CM_ "IMPORT _hyundai_common.dbc";

BO_ 53 ACCELERATOR: 32 XXX
 SG_ CHECKSUM : 0|16@1+ (1,0) [0|65535] "" XXX
 SG_ COUNTER : 16|8@1+ (1,0) [0|255] "" XXX
 SG_ ACCELERATOR_PEDAL : 40|8@1+ (1,0) [0|255] "" XXX
 SG_ GEAR : 192|3@1+ (1,0) [0|7] "" XXX

BO_ 64 GEAR_ALT: 32 XXX
 SG_ CHECKSUM : 0|16@1+ (1,0) [0|65535] "" XXX
 SG_ COUNTER : 16|8@1+ (1,0) [0|255] "" XXX
 SG_ GEAR : 32|3@1+ (1,0) [0|7] "" XXX

BO_ 69 GEAR: 24 XXX
 SG_ CHECKSUM : 0|16@1+ (1,0) [0|65535] "" XXX
 SG_ COUNTER : 16|8@1+ (1,0) [0|255] "" XXX
 SG_ GEAR : 44|3@1+ (1,0) [0|7] "" XXX

BO_ 74 IMU_01_10ms: 32 CGW_CCU
 SG_ IMU_Crc1Val : 0|16@1+ (1,0) [0|0] "" ECS,ESC,FCU_C,GW_RGW,ICSC,MDPS,RCU,RWS,SFA,VPC_C
 SG_ IMU_AlvCnt1Val : 16|8@1+ (1,0) [0|0] "" ECS,ESC,FCU_C,GW_RGW,ICSC,MDPS,RCU,RWS,SFA,VPC_C
 SG_ IMU_YawSigSta : 24|4@1+ (1,0) [0|0] "" ESC,FCU_C,GW_RGW,MDPS,RCU,RWS,SFA,VPC_C
 SG_ IMU_LatAccelSigSta : 28|4@1+ (1,0) [0|0] "" ECS,ESC,FCU
 SG_ IMU_YawRtVal : 64|16@1+ (0.005,-163.84) [0|0] "º/s" ESC,FCU_C,GW_RGW,ICSC,MDPS,RCU,RWS,SFA,VPC_C
 SG_ IMU_LatAccelVal : 80|16@1+ (0.000127465,-4.17677312) [0|0] "g" ECS,ESC,FCU_C,GW_RGW,ICSC,MDPS,RCU,RWS,SFA,VPC_C

BO_ 96 ESP_STATUS: 32 XXX
 SG_ CHECKSUM : 0|16@1+ (1,0) [0|65535] "" XXX
 SG_ COUNTER : 16|8@1+ (1,0) [0|255] "" XXX
 SG_ TRACTION_AND_STABILITY_CONTROL : 42|3@1+ (1,0) [0|63] "" XXX
 SG_ BRAKE_PRESSURE : 128|10@1+ (1,0) [0|65535] "" XXX
 SG_ BRAKE_PRESSED : 148|1@1+ (1,0) [0|3] "" XXX

BO_ 101 BRAKE: 32 XXX
 SG_ CHECKSUM : 0|16@1+ (1,0) [0|65535] "" XXX
 SG_ COUNTER : 16|8@1+ (1,0) [0|255] "" XXX
 SG_ BRAKE_POSITION : 40|16@1- (1,0) [0|65535] "" XXX
 SG_ BRAKE_PRESSED : 57|1@1+ (1,0) [0|3] "" XXX

BO_ 112 GEAR_ALT_2: 32 XXX
 SG_ CHECKSUM : 0|16@1+ (1,0) [0|65535] "" XXX
 SG_ COUNTER : 16|8@1+ (1,0) [0|255] "" XXX
 SG_ GEAR : 60|3@1+ (1,0) [0|7] "" XXX

BO_ 160 WHL_01_10ms: 24 XXX
 SG_ WHL_Crc1Val : 0|16@1+ (1,0) [0|65535] "" XXX
 SG_ WHL_AlvCnt1Val : 16|8@1+ (1,0) [0|255] "" XXX
 SG_ WHL_PlsFLVal : 24|8@1+ (1,0) [0|255] "" XXX
 SG_ WHL_PlsFRVal : 32|8@1+ (1,0) [0|255] "" XXX
 SG_ WHL_PlsRLVal : 40|8@1+ (1,0) [0|255] "" XXX
 SG_ WHL_PlsRRVal : 48|8@1+ (1,0) [0|255] "" XXX
 SG_ WHL_DirFLVal : 56|2@1+ (1,0) [0|3] "" XXX
 SG_ WHL_DirFRVal : 58|2@1+ (1,0) [0|2] "" XXX
 SG_ WHL_DirRLVal : 60|2@1+ (1,0) [0|3] "" XXX
 SG_ WHL_DirRRVal : 62|2@1+ (1,0) [0|3] "" XXX
 SG_ WHL_SpdFLVal : 64|14@1+ (0.03125,0) [0|0] "km^h" XXX
 SG_ WHL_SpdFRVal : 80|14@1+ (0.03125,0) [0|0] "km^h" XXX
 SG_ WHL_SpdRLVal : 96|14@1+ (0.03125,0) [0|0] "km^h" XXX
 SG_ WHL_SpdRRVal : 112|14@1+ (0.03125,0) [0|0] "km^h" XXX
 SG_ WHL_SpdCalParmtr : 136|8@1+ (1,0) [0|255] "" XXX

BO_ 203 ADAS_CMD_35_10ms: 24 CGW_CCU
 SG_ ADAS_CMD_Crc35Val : 0|16@1+ (1,0) [0|0] "0" FCU_C,GW_RGW,MDPS,SFA
 SG_ ADAS_CMD_AlvCnt35Val : 16|8@1+ (1,0) [0|0] "0" FCU_C,GW_RGW,MDPS,SFA
 SG_ ADAS_ActvACISta : 24|4@1+ (1,0) [0|0] "" GW_RGW,MDPS,SFA
 SG_ ADAS_ActvACILvl2Sta : 28|4@1+ (1,0) [0|0] "" ESC,FCU_C,GW_RGW,MDPS,SFA,VPC_C
 SG_ ADAS_StrAnglReqVal : 32|14@1- (0.1,0) [0|0] "Deg" GW_RGW,MDPS,SFA
 SG_ ADAS_ACIAnglTqRedcGainVal : 48|8@1+ (0.004,0) [0|0] "" GW_RGW,MDPS,SFA
 SG_ FCA_ESA_ActvSta : 56|2@1+ (1,0) [0|0] "" GW_RGW,MDPS,SFA
 SG_ FCA_ESA_TqBstGainVal : 64|8@1+ (0.004,0) [0|0] "" GW_RGW,MDPS,SFA

BO_ 234 MDPS_01_10ms: 24 XXX
 SG_ MDPS_Crc1Val : 0|16@1+ (1,0) [0|0] "" XXX
 SG_ MDPS_AlvCnt1Val : 16|8@1+ (1,0) [0|0] "" XXX
 SG_ MDPS_WrngLmpSta : 24|3@1+ (1,0) [0|0] "" XXX
 SG_ MDPS_Typ : 27|3@1+ (1,0) [0|0] "" XXX
 SG_ MDPS_EngIdleRpmReq : 30|2@1+ (1,0) [0|0] "" XXX
 SG_ MDPS_VsmPlgInSta : 32|2@1+ (1,0) [0|0] "flag" XXX
 SG_ MDPS_VsmDfctvSta : 34|2@1+ (1,0) [0|0] "" XXX
 SG_ MDPS_VsmSigErrSta : 36|2@1+ (1,0) [0|0] "" XXX
 SG_ MDPS_PaPlugInSta : 38|2@1+ (1,0) [0|0] "" XXX
 SG_ MDPS_PaModeSta : 40|4@1+ (1,0) [0|0] "" XXX
 SG_ MDPS_PaCanfltSta : 44|2@1+ (1,0) [0|0] "" XXX
 SG_ MDPS_LkaPlgInSta : 46|2@1+ (1,0) [0|0] "" XXX
 SG_ MDPS_LkaToiActvSta : 48|2@1+ (1,0) [0|0] "" XXX
 SG_ MDPS_LkaToiUnblSta : 50|2@1+ (1,0) [0|0] "" XXX
 SG_ MDPS_LkaToiFltSta : 52|2@1+ (1,0) [0|0] "" XXX
 SG_ MDPS_LkaFailSta : 54|2@1+ (1,0) [0|0] "" XXX
 SG_ MDPS_ResetOpSta : 59|2@1+ (1,0) [0|0] "" XXX
 SG_ MDPS_CurrModVal : 61|3@1+ (1,0) [0|0] "" XXX
 SG_ MDPS_OutTqVal : 64|12@1+ (0.1,-204.8) [0|0] "Nm" XXX
 SG_ MDPS_VsmActResp : 76|2@1+ (1,0) [0|0] "" XXX
 SG_ Reprogram_State_MDPS : 78|2@1+ (1,0) [0|0] "" XXX
 SG_ MDPS_StrTqSnsrVal : 80|13@1+ (0.005,-20.48) [0|0] "Nm" XXX
 SG_ MDPS_PaStrAnglVal : 96|16@1- (0.1,0) [0|0] "Deg" XXX
 SG_ MDPS_LoamModSta : 112|2@1+ (1,0) [0|0] "" XXX
 SG_ MDPS_HDPSpprtSWVer : 114|5@1+ (1,0) [0|0] "" XXX
 SG_ MDPS_ADASAciActvSta : 120|4@1+ (1,0) [0|0] "" XXX
 SG_ MDPS_ADASAciPluginSta : 124|2@1+ (1,0) [0|0] "" XXX
 SG_ MDPS_ADAS_AciFltSig : 126|2@1+ (1,0) [0|0] "" XXX
 SG_ MDPS_EstStrAnglVal : 128|16@1- (0.1,0) [0|0] "Deg" XXX
 SG_ MDPS_ADASAciActvSta_Lv2 : 144|4@1+ (1,0) [0|0] "" XXX
 SG_ MDPS_ADAS_AciFltSig_Lv2 : 148|3@1+ (1,0) [0|0] "" XXX
 SG_ MDPS_TpaPlugInSta : 152|2@1+ (1,0) [0|0] "" XXX
 SG_ MDPS_TpaCanfltSta : 154|2@1+ (1,0) [0|0] "" XXX
 SG_ MDPS_TpaModeSta : 156|4@1+ (1,0) [0|0] "" XXX
 SG_ MDPS_TpaStrAnglVal : 160|16@1- (0.1,0) [0|0] "Deg" XXX

BO_ 256 ACCELERATOR_BRAKE_ALT: 32 XXX
 SG_ CHECKSUM : 0|16@1+ (1,0) [0|65535] "" XXX
 SG_ COUNTER : 16|8@1+ (1,0) [0|255] "" XXX
 SG_ BRAKE_PRESSED : 32|1@1+ (1,0) [0|1] "" XXX
 SG_ ACCELERATOR_PEDAL_PRESSED : 176|1@1+ (1,0) [0|1] "" XXX

BO_ 261 ACCELERATOR_ALT: 32 XXX
 SG_ CHECKSUM : 0|16@1+ (1,0) [0|65535] "" XXX
 SG_ COUNTER : 16|8@1+ (1,0) [0|255] "" XXX
 SG_ ACCELERATOR_PEDAL : 103|10@1+ (0.25,0) [0|1022] "" XXX

BO_ 272 LKAS_ALT: 32 XXX
 SG_ CHECKSUM : 0|16@1+ (1,0) [0|65535] "" XXX
 SG_ COUNTER : 16|8@1+ (1,0) [0|255] "" XXX
 SG_ LKA_MODE : 24|3@1+ (1,0) [0|7] "" XXX
 SG_ LKA_AVAILABLE : 27|2@1+ (1,0) [0|255] "" XXX
 SG_ LKA_WARNING : 32|1@1+ (1,0) [0|1] "" XXX
 SG_ LKA_ICON : 38|2@1+ (1,0) [0|255] "" XXX
 SG_ FCA_SYSWARN : 40|1@0+ (1,0) [0|1] "" XXX
 SG_ TORQUE_REQUEST : 41|11@1+ (1,-1024) [0|4095] "" XXX
 SG_ STEER_REQ : 52|1@1+ (1,0) [0|1] "" XXX
 SG_ LFA_BUTTON : 56|1@1+ (1,0) [0|255] "" XXX
 SG_ LKA_ASSIST : 62|1@1+ (1,0) [0|1] "" XXX
 SG_ STEER_MODE : 65|3@1+ (1,0) [0|1] "" XXX
 SG_ NEW_SIGNAL_2 : 70|2@0+ (1,0) [0|3] "" XXX
 SG_ LKAS_ANGLE_ACTIVE : 77|2@0+ (1,0) [0|3] "" XXX
 SG_ HAS_LANE_SAFETY : 80|1@0+ (1,0) [0|1] "" XXX
 SG_ LKAS_ANGLE_CMD : 82|14@1- (0.1,0) [0|511] "" XXX
 SG_ LKAS_ANGLE_MAX_TORQUE : 96|8@1+ (1,0) [0|255] "" XXX
 SG_ NEW_SIGNAL_3 : 111|8@0+ (1,0) [0|255] "" XXX

BO_ 293 SAS_01_10ms: 16 XXX
 SG_ SAS_Crc1Val : 0|16@1+ (1,0) [0|0] "" XXX
 SG_ SAS_AlvCnt1Val : 16|8@1+ (1,0) [0|0] "" XXX
 SG_ SAS_AnglVal : 24|16@1- (0.1,0) [0|0] "Deg" XXX
 SG_ SAS_SpdVal : 40|8@1+ (4,0) [0|0] "Deg/s" XXX
 SG_ SAS_IntSta : 48|8@1+ (1,0) [0|0] "" XXX

BO_ 298 ADAS_CMD_30_10ms: 16 ADRV
 SG_ ADAS_CMD_Crc30Val : 0|16@1+ (1,0) [0|65535] "" ADRV
 SG_ ADAS_CMD_AlvCnt30Val : 16|8@1+ (1,0) [0|255] "" ADRV
 SG_ LKA_OptUsmSta : 24|3@1+ (1,0) [0|7] "" ADRV
 SG_ LKA_RcgSta : 27|2@1+ (1,0) [0|255] "" ADRV
 SG_ LKA_LHLnWrnSta : 30|2@1+ (1,0) [0|3] "" ADRV
 SG_ LKA_RHLnWrnSta : 32|1@1+ (1,0) [0|1] "" ADRV
 SG_ LKA_HndsoffSnd : 34|4@1+ (1,0) [0|15] "" ADRV
 SG_ LKA_SysIndReq : 38|2@1+ (1,0) [0|255] "" ADRV
 SG_ ADAS_StrTqReqVal : 41|11@1+ (1,-1024) [0|4095] "" ADRV
 SG_ ADAS_ActToiSta : 52|1@1+ (1,0) [0|1] "" ADRV
 SG_ ADAS_ToiFltSta : 54|2@1+ (1,0) [0|3] "" ADRV
 SG_ LFA_BUTTON : 56|1@1+ (1,0) [0|255] "" ADRV
 SG_ LKA_SysWrn : 60|2@1+ (1,0) [0|3] "" ADRV
 SG_ LKA_ASSIST : 62|1@1+ (1,0) [0|1] "" ADRV
 SG_ FCA_LO_WrnSta : 64|1@1+ (1,0) [0|1] "" ADRV
 SG_ STEER_MODE : 65|3@1+ (1,0) [0|1] "" ADRV
 SG_ FCA_LS_WrnSta : 68|2@1+ (1,0) [0|3] "" ADRV
 SG_ NEW_SIGNAL_2 : 70|2@0+ (1,0) [0|3] "" ADRV
 SG_ SCC_TakeoverReq_CLU_AMP_PE_02_Warn_Sound : 72|8@1+ (1,0) [0|255] "" ADRV
 SG_ LKA_UsmMod : 80|1@0+ (1,0) [0|1] "" ADRV
 SG_ ELK_SysFlrSta : 85|5@1+ (1,0) [0|31] "" ADRV
 SG_ ELK_SymbDisp : 90|3@1+ (1,0) [0|7] "" ADRV
 SG_ FCA_ESA_WrnSta : 93|8@1+ (1,0) [0|255] "" ADRV
 SG_ FCA_ESA_CtrlSta : 101|3@1+ (1,0) [0|7] "" ADRV
 SG_ ADAS_Damping_Gain : 104|7@1+ (1,0) [0|127] "" ADRV
 SG_ NEW_SIGNAL_3 : 111|8@0+ (1,0) [0|255] "" ADRV

BO_ 304 GEAR_SHIFTER: 16 XXX
 SG_ CHECKSUM : 0|16@1+ (1,0) [0|65535] "" XXX
 SG_ COUNTER : 16|8@1+ (1,0) [0|255] "" XXX
 SG_ PARK_BUTTON : 32|2@1+ (1,0) [0|3] "" XXX
 SG_ KNOB_POSITION : 40|3@1+ (1,0) [0|3] "" XXX
 SG_ GEAR : 64|3@1+ (1,0) [0|7] "" XXX

BO_ 352 ADRV_0x160: 16 ADRV
 SG_ CHECKSUM : 0|16@1+ (1,0) [0|65535] "" XXX
 SG_ COUNTER : 16|8@1+ (1,0) [0|255] "" XXX
 SG_ AEB_SETTING : 24|2@1+ (1,0) [0|255] "" XXX
 SG_ SET_ME_2 : 56|8@1+ (1,0) [0|1] "" XXX
 SG_ SET_ME_FF : 64|8@1+ (1,0) [0|255] "" XXX
 SG_ SET_ME_FC : 72|8@1+ (1,0) [0|255] "" XXX
 SG_ SET_ME_9 : 80|8@1+ (1,0) [0|255] "" XXX

BO_ 353 CCNC_0x161: 32 CCNC
 SG_ CHECKSUM : 0|16@1+ (1,0) [0|65535] "" XXX
 SG_ COUNTER : 16|8@1+ (1,0) [0|255] "" XXX
 SG_ FCA_ICON : 24|3@1+ (1,0) [0|7] "" XXX
 SG_ FCA_ALT_ICON : 27|3@1+ (1,0) [0|7] "" XXX
 SG_ LKA_ICON : 30|3@1+ (1,0) [0|3] "" XXX
 SG_ HBA_ICON : 33|3@1+ (1,0) [0|7] "" XXX
 SG_ ZEROS_1 : 36|4@1+ (1,0) [0|15] "" XXX
 SG_ ZEROS_2 : 40|2@1+ (1,0) [0|3] "" XXX
 SG_ FCA_IMAGE : 42|3@1+ (1,0) [0|7] "" XXX
 SG_ ZEROS_3 : 45|3@1+ (1,0) [0|7] "" XXX
 SG_ ZEROS_4 : 48|3@1+ (1,0) [0|7] "" XXX
 SG_ BCA_LEFT : 51|3@1+ (1,0) [0|7] "" XXX
 SG_ BCA_RIGHT : 54|3@1+ (1,0) [0|7] "" XXX
 SG_ LCA_LEFT_ARROW : 57|3@1+ (1,0) [0|7] "" XXX
 SG_ LCA_RIGHT_ARROW : 60|3@1+ (1,0) [0|7] "" XXX
 SG_ ZEROS_5 : 63|1@0+ (1,0) [0|1] "" XXX
 SG_ CENTERLINE : 64|2@1+ (1,0) [0|3] "" XXX
 SG_ TARGET : 66|3@1+ (1,0) [0|7] "" XXX
 SG_ TARGET_DISTANCE : 69|11@1+ (0.1,0) [0|204.7] "m" XXX
 SG_ LANELINE_LEFT : 80|4@1+ (1,0) [0|15] "" XXX
 SG_ LANELINE_LEFT_POSITION : 84|6@1+ (1,0) [0|15] "" XXX
 SG_ LANELINE_RIGHT : 90|4@1+ (1,0) [0|15] "" XXX
 SG_ LANELINE_RIGHT_POSITION : 94|6@1+ (1,0) [0|3] "" XXX
 SG_ LANELINE_CURVATURE : 100|5@1- (1,15) [0|31] "" XXX
 SG_ LANE_HIGHLIGHT : 105|4@1+ (1,0) [0|15] "" XXX
 SG_ LANE_HIGHLIGHT_DISTANCE : 109|11@1+ (0.1,0) [0|204.7] "m" XXX
 SG_ LANE_LEFT : 120|3@1+ (1,0) [0|7] "" XXX
 SG_ LANE_RIGHT : 123|3@1+ (1,0) [0|7] "" XXX
 SG_ LANE_ZOOM : 126|2@1+ (1,0) [0|3] "" XXX
 SG_ ALERTS_1 : 128|6@1+ (1,0) [0|63] "" XXX
 SG_ ALERTS_2 : 134|5@1+ (1,0) [0|3] "" XXX
 SG_ ALERTS_3 : 139|5@1+ (1,0) [0|15] "" XXX
 SG_ ALERTS_4 : 144|8@1+ (1,0) [0|511] "" XXX
 SG_ ALERTS_5 : 152|5@1+ (1,0) [0|7] "" XXX
 SG_ MUTE : 157|3@1+ (1,0) [0|7] "" XXX
 SG_ SOUNDS_1 : 160|4@1+ (1,0) [0|3] "" XXX
 SG_ SOUNDS_2 : 164|4@1+ (1,0) [0|3] "" XXX
 SG_ SOUNDS_3 : 168|4@1+ (1,0) [0|15] "" XXX
 SG_ SOUNDS_4 : 172|3@1+ (1,0) [0|7] "" XXX
 SG_ ZEROS_6 : 175|1@0+ (1,0) [0|1] "" XXX
 SG_ ZEROS_7 : 176|5@1+ (1,0) [0|31] "" XXX
 SG_ SETSPEED_HUD : 181|3@1+ (1,0) [0|3] "" XXX
 SG_ DISTANCE_LEAD : 184|5@1+ (1,0) [0|31] "" XXX
 SG_ DISTANCE_CAR : 189|3@1+ (1,0) [0|7] "" XXX
 SG_ DISTANCE_SPACING : 192|4@1+ (1,0) [0|15] "" XXX
 SG_ DISTANCE : 196|4@1+ (1,0) [0|7] "" XXX
 SG_ SETSPEED_SPEED : 200|8@1+ (1,0) [0|255] "" XXX
 SG_ SETSPEED : 208|4@1+ (1,0) [0|3] "" XXX
 SG_ HDA_ICON : 212|4@1+ (1,0) [0|3] "" XXX
 SG_ SLA_ICON : 216|4@1+ (1,0) [0|15] "" XXX
 SG_ NAV_ICON : 220|4@1+ (1,0) [0|3] "" XXX
 SG_ LFA_ICON : 224|4@1+ (1,0) [0|3] "" XXX
 SG_ LCA_LEFT_ICON : 228|4@1+ (1,0) [0|15] "" XXX
 SG_ LCA_RIGHT_ICON : 232|4@1+ (1,0) [0|15] "" XXX
 SG_ BACKGROUND : 236|4@1+ (1,0) [0|15] "" XXX
 SG_ DAW_ICON : 240|3@1+ (1,0) [0|7] "" XXX
 SG_ CAR_CIRCLE : 243|3@1+ (1,0) [0|7] "" XXX
 SG_ ZEROS_8 : 246|2@1+ (1,0) [0|3] "" XXX
 SG_ ZEROS_9 : 248|8@1+ (1,0) [0|255] "" XXX

BO_ 354 CCNC_0x162: 32 CCNC
 SG_ CHECKSUM : 0|16@1+ (1,0) [0|65535] "" XXX
 SG_ COUNTER : 16|8@1+ (1,0) [0|255] "" XXX
 SG_ COUNTRY : 24|4@1+ (1,0) [0|7] "" XXX
 SG_ SPEEDLIMIT_FLASH : 28|4@1+ (1,0) [0|15] "" XXX
 SG_ SPEEDLIMIT : 32|8@1+ (1,0) [0|255] "" XXX
 SG_ SIGNS : 40|8@1+ (1,0) [0|15] "" XXX
 SG_ SPEEDLIMIT_WEATHER : 48|4@1+ (1,0) [0|15] "" XXX
 SG_ VIBRATE : 52|3@1+ (1,0) [0|7] "" XXX
 SG_ ZEROS_1 : 55|1@0+ (1,0) [0|1] "" XXX
 SG_ ZEROS_2 : 56|8@1+ (1,0) [0|255] "" XXX
 SG_ LEAD : 64|5@1+ (1,0) [0|31] "" XXX
 SG_ LEAD_DISTANCE : 69|11@1+ (0.1,0) [0|204.7] "m" XXX
 SG_ LEAD_LATERAL : 80|7@1+ (0.1,0) [0|127] "m" XXX
 SG_ ZEROS_3 : 87|1@0+ (1,0) [0|1] "" XXX
 SG_ LEAD_ALT : 88|5@1+ (1,0) [0|31] "" XXX
 SG_ LEAD_ALT_DISTANCE : 93|11@1+ (0.1,0) [0|204.7] "m" XXX
 SG_ LEAD_ALT_LATERAL : 104|7@1+ (0.1,0) [0|127] "m" XXX
 SG_ ZEROS_4 : 111|1@0+ (1,0) [0|1] "" XXX
 SG_ LEAD_LEFT : 112|5@1+ (1,0) [0|31] "" XXX
 SG_ LEAD_LEFT_DISTANCE : 117|11@1+ (0.1,0) [0|204.7] "m" XXX
 SG_ LEAD_LEFT_LATERAL : 128|7@1+ (0.1,0) [0|127] "m" XXX
 SG_ ZEROS_5 : 135|1@0+ (1,0) [0|1] "" XXX
 SG_ LEAD_RIGHT : 136|5@1+ (1,0) [0|31] "" XXX
 SG_ LEAD_RIGHT_DISTANCE : 141|11@1+ (0.1,0) [0|204.7] "m" XXX
 SG_ LEAD_RIGHT_LATERAL : 152|7@1+ (0.1,0) [0|127] "m" XXX
 SG_ ZEROS_6 : 159|1@0+ (1,0) [0|1] "" XXX
 SG_ ZEROS_7 : 162|3@0+ (1,0) [0|7] "" XXX
 SG_ LEAD_LEFT_REAR_STATUS : 167|5@0+ (1,0) [0|31] "" XXX
 SG_ LEAD_LEFT_REAR_DISTANCE : 175|8@0+ (0.1,0) [0|255] "m" XXX
 SG_ LEAD_LEFT_REAR_LATERAL : 182|7@0+ (0.1,0) [0|127] "m" XXX
 SG_ ZEROS_8 : 183|1@0+ (1,0) [0|1] "" XXX
 SG_ ZEROS_9 : 191|8@0+ (1,0) [0|255] "" XXX
 SG_ LEAD_RIGHT_REAR_STATUS : 196|5@0+ (1,0) [0|31] "" XXX
 SG_ LEAD_RIGHT_REAR_DISTANCE : 197|8@1+ (0.1,0) [0|255] "m" XXX
 SG_ LEAD_RIGHT_REAR_LATERAL : 205|7@1+ (0.1,0) [0|127] "m" XXX
 SG_ ZEROS_10 : 212|1@0+ (1,0) [0|1] "" XXX
 SG_ FAULT_FSS : 213|3@1+ (1,0) [0|7] "" XXX
 SG_ FAULT_FCA : 216|3@1+ (1,0) [0|7] "" XXX
 SG_ FAULT_LSS : 219|3@1+ (1,0) [0|7] "" XXX
 SG_ FAULT_SLA : 222|3@1+ (1,0) [0|7] "" XXX
 SG_ FAULT_DAW : 225|3@1+ (1,0) [0|7] "" XXX
 SG_ FAULT_HBA : 228|3@1+ (1,0) [0|7] "" XXX
 SG_ FAULT_SCC : 231|3@1+ (1,0) [0|7] "" XXX
 SG_ FAULT_LFA : 234|3@1+ (1,0) [0|7] "" XXX
 SG_ FAULT_HDA : 237|3@1+ (1,0) [0|7] "" XXX
 SG_ FAULT_LCA : 240|3@1+ (1,0) [0|7] "" XXX
 SG_ FAULT_HDP : 243|3@1+ (1,0) [0|7] "" XXX
 SG_ FAULT_DAS : 246|3@1+ (1,0) [0|7] "" XXX
 SG_ FAULT_ESS : 249|3@1+ (1,0) [0|7] "" XXX
 SG_ ZEROS_11 : 252|4@1+ (1,0) [0|15] "" XXX

BO_ 357 SPAS1: 24 APRK
 SG_ CHECKSUM : 0|16@1+ (1,0) [0|65535] "" XXX
 SG_ COUNTER : 16|8@1+ (1,0) [0|0] "" XXX
 SG_ NEW_SIGNAL_2 : 90|3@1+ (1,0) [0|0] "" XXX
 SG_ NEW_SIGNAL_1 : 96|16@1- (0.1,0) [0|0] "" XXX

BO_ 362 SPAS2: 32 APRK
 SG_ CHECKSUM : 0|16@1+ (1,0) [0|65535] "" XXX
 SG_ COUNTER : 16|8@1+ (1,0) [0|0] "" XXX
 SG_ BLINKER_CONTROL : 133|3@1+ (1,0) [0|0] "" XXX

BO_ 373 TCS: 24 XXX
 SG_ CHECKSUM : 0|16@1+ (1,0) [0|65535] "" XXX
 SG_ COUNTER : 16|8@1+ (1,0) [0|255] "" XXX
 SG_ NEW_SIGNAL_4 : 24|7@1+ (1,0) [0|127] "" XXX
 SG_ aBasis : 32|11@1+ (0.01,-10.23) [0|7] "m/s^2" XXX
 SG_ ACCEL_REF_ACC : 48|11@1- (1,0) [0|1023] "" XXX
 SG_ EQUIP_MAYBE : 64|1@0+ (1,0) [0|1] "" XXX
 SG_ ACCEnable : 67|2@0+ (1,0) [0|3] "" XXX
 SG_ ACC_REQ : 68|1@0+ (1,0) [0|1] "" XXX
 SG_ NEW_SIGNAL_5 : 72|1@0+ (1,0) [0|1] "" XXX
 SG_ NEW_SIGNAL_2 : 74|1@0+ (1,0) [0|1] "" XXX
 SG_ NEW_SIGNAL_3 : 76|1@0+ (1,0) [0|1] "" XXX
 SG_ NEW_SIGNAL_1 : 80|1@0+ (1,0) [0|1] "" XXX
 SG_ DriverBraking : 81|1@0+ (1,0) [0|1] "" XXX
 SG_ DriverBrakingLowSens : 84|1@1+ (1,0) [0|1] "" XXX
 SG_ AEB_EQUIP_MAYBE : 96|1@0+ (1,0) [0|1] "" XXX
 SG_ NEW_SIGNAL_6 : 128|4@1+ (1,0) [0|15] "" XXX
 SG_ NEW_SIGNAL_7 : 135|2@0+ (1,0) [0|3] "" XXX
 SG_ PROBABLY_EQUIP : 136|2@1+ (1,0) [0|3] "" XXX

BO_ 384 L_FR_CMR_Obj_01_30ms: 32 FR_CMR
 SG_ FR_CMR_Obj_Crc01Val : 0|16@1+ (1,0) [0|65535] "" ADAS_DRV
 SG_ FR_CMR_Obj_AlvCnt01Val : 16|8@1+ (1,0) [0|255] "" ADAS_DRV
 SG_ FR_CMR_Obj_QualLvl01Sta : 24|7@1+ (1,0) [0|100] "%" ADAS_DRV
 SG_ FR_CMR_Obj_AlvAge01Val : 32|8@1+ (1,0) [0|255] "" ADAS_DRV
 SG_ FR_CMR_Obj_MvngFlag01Sta : 40|4@1+ (1,0) [0|9] "" ADAS_DRV
 SG_ FR_CMR_Obj_Id01Val : 44|7@1+ (1,0) [0|127] "" ADAS_DRV
 SG_ FR_CMR_Obj_Wth01Val : 52|7@1+ (0.05,0) [0|6.35] "m" ADAS_DRV
 SG_ FR_CMR_Obj_Clfct01Sta : 60|3@1+ (1,0) [0|6] "" ADAS_DRV
 SG_ FR_CMR_Obj_RelPosX01Val : 64|13@1+ (0.05,0) [0|350] "m" ADAS_DRV
 SG_ FR_CMR_Obj_RelPosY01Val : 78|12@1+ (0.05,-102.4) [-102.4|102.35] "m" ADAS_DRV
 SG_ FR_CMR_Obj_RelVelX01Val : 91|12@1+ (0.05,-100) [-100|100] "m/s" ADAS_DRV
 SG_ FR_CMR_Obj_RelVelY01Val : 104|10@1+ (0.05,-25) [-25|25] "m/s" ADAS_DRV
 SG_ FR_CMR_Obj_RelAccelX01Val : 115|9@1- (0.05,0) [-12.8|12.75] "m/s^2" ADAS_DRV
 SG_ FR_CMR_Obj_QualLvl02Sta : 152|7@1+ (1,0) [0|100] "%" ADAS_DRV
 SG_ FR_CMR_Obj_AlvAge02Val : 160|8@1+ (1,0) [0|255] "" ADAS_DRV
 SG_ FR_CMR_Obj_MvngFlag02Sta : 168|4@1+ (1,0) [0|9] "" ADAS_DRV
 SG_ FR_CMR_Obj_Id02Val : 172|7@1+ (1,0) [0|127] "" ADAS_DRV
 SG_ FR_CMR_Obj_Wth02Val : 180|7@1+ (0.05,0) [0|6.35] "m" ADAS_DRV
 SG_ FR_CMR_Obj_Clfct02Sta : 188|3@1+ (1,0) [0|6] "" ADAS_DRV
 SG_ FR_CMR_Obj_RelPosX02Val : 192|13@1+ (0.05,0) [0|350] "m" ADAS_DRV
 SG_ FR_CMR_Obj_RelPosY02Val : 206|12@1+ (0.05,-102.4) [-102.4|102.35] "m" ADAS_DRV
 SG_ FR_CMR_Obj_RelVelX02Val : 219|12@1+ (0.05,-100) [-100|100] "m/s" ADAS_DRV
 SG_ FR_CMR_Obj_RelVelY02Val : 232|10@1+ (0.05,-25) [-25|25] "m/s" ADAS_DRV
 SG_ FR_CMR_Obj_RelAccelX02Val : 243|9@1- (0.05,0) [-12.8|12.75] "m/s^2" ADAS_DRV

BO_ 385 L_FR_CMR_Obj_02_30ms: 32 FR_CMR
 SG_ FR_CMR_Obj_Crc02Val : 0|16@1+ (1,0) [0|65535] "" ADAS_DRV
 SG_ FR_CMR_Obj_AlvCnt02Val : 16|8@1+ (1,0) [0|255] "" ADAS_DRV
 SG_ FR_CMR_Obj_QualLvl03Sta : 24|7@1+ (1,0) [0|100] "%" ADAS_DRV
 SG_ FR_CMR_Obj_AlvAge03Val : 32|8@1+ (1,0) [0|255] "" ADAS_DRV
 SG_ FR_CMR_Obj_MvngFlag03Sta : 40|4@1+ (1,0) [0|9] "" ADAS_DRV
 SG_ FR_CMR_Obj_Id03Val : 44|7@1+ (1,0) [0|127] "" ADAS_DRV
 SG_ FR_CMR_Obj_Wth03Val : 52|7@1+ (0.05,0) [0|6.35] "m" ADAS_DRV
 SG_ FR_CMR_Obj_Clfct03Sta : 60|3@1+ (1,0) [0|6] "" ADAS_DRV
 SG_ FR_CMR_Obj_RelPosX03Val : 64|13@1+ (0.05,0) [0|350] "m" ADAS_DRV
 SG_ FR_CMR_Obj_RelPosY03Val : 78|12@1+ (0.05,-102.4) [-102.4|102.35] "m" ADAS_DRV
 SG_ FR_CMR_Obj_RelVelX03Val : 91|12@1+ (0.05,-100) [-100|100] "m/s" ADAS_DRV
 SG_ FR_CMR_Obj_RelVelY03Val : 104|10@1+ (0.05,-25) [-25|25] "m/s" ADAS_DRV
 SG_ FR_CMR_Obj_RelAccelX03Val : 115|9@1- (0.05,0) [-12.8|12.75] "m/s^2" ADAS_DRV
 SG_ FR_CMR_Obj_QualLvl04Sta : 152|7@1+ (1,0) [0|100] "%" ADAS_DRV
 SG_ FR_CMR_Obj_AlvAge04Val : 160|8@1+ (1,0) [0|255] "" ADAS_DRV
 SG_ FR_CMR_Obj_MvngFlag04Sta : 168|4@1+ (1,0) [0|9] "" ADAS_DRV
 SG_ FR_CMR_Obj_Id04Val : 172|7@1+ (1,0) [0|127] "" ADAS_DRV
 SG_ FR_CMR_Obj_Wth04Val : 180|7@1+ (0.05,0) [0|6.35] "m" ADAS_DRV
 SG_ FR_CMR_Obj_Clfct04Sta : 188|3@1+ (1,0) [0|6] "" ADAS_DRV
 SG_ FR_CMR_Obj_RelPosX04Val : 192|13@1+ (0.05,0) [0|350] "m" ADAS_DRV
 SG_ FR_CMR_Obj_RelPosY04Val : 206|12@1+ (0.05,-102.4) [-102.4|102.35] "m" ADAS_DRV
 SG_ FR_CMR_Obj_RelVelX04Val : 219|12@1+ (0.05,-100) [-100|100] "m/s" ADAS_DRV
 SG_ FR_CMR_Obj_RelVelY04Val : 232|10@1+ (0.05,-25) [-25|25] "m/s" ADAS_DRV
 SG_ FR_CMR_Obj_RelAccelX04Val : 243|9@1- (0.05,0) [-12.8|12.75] "m/s^2" ADAS_DRV

BO_ 386 L_FR_CMR_Obj_03_30ms: 32 FR_CMR
 SG_ FR_CMR_Obj_Crc03Val : 0|16@1+ (1,0) [0|65535] "" ADAS_DRV
 SG_ FR_CMR_Obj_AlvCnt03Val : 16|8@1+ (1,0) [0|255] "" ADAS_DRV
 SG_ FR_CMR_Obj_QualLvl05Sta : 24|7@1+ (1,0) [0|100] "%" ADAS_DRV
 SG_ FR_CMR_Obj_AlvAge05Val : 32|8@1+ (1,0) [0|255] "" ADAS_DRV
 SG_ FR_CMR_Obj_MvngFlag05Sta : 40|4@1+ (1,0) [0|9] "" ADAS_DRV
 SG_ FR_CMR_Obj_Id05Val : 44|7@1+ (1,0) [0|127] "" ADAS_DRV
 SG_ FR_CMR_Obj_Wth05Val : 52|7@1+ (0.05,0) [0|6.35] "m" ADAS_DRV
 SG_ FR_CMR_Obj_Clfct05Sta : 60|3@1+ (1,0) [0|6] "" ADAS_DRV
 SG_ FR_CMR_Obj_RelPosX05Val : 64|13@1+ (0.05,0) [0|350] "m" ADAS_DRV
 SG_ FR_CMR_Obj_RelPosY05Val : 78|12@1+ (0.05,-102.4) [-102.4|102.35] "m" ADAS_DRV
 SG_ FR_CMR_Obj_RelVelX05Val : 91|12@1+ (0.05,-100) [-100|100] "m/s" ADAS_DRV
 SG_ FR_CMR_Obj_RelVelY05Val : 104|10@1+ (0.05,-25) [-25|25] "m/s" ADAS_DRV
 SG_ FR_CMR_Obj_RelAccelX05Val : 115|9@1- (0.05,0) [-12.8|12.75] "m/s^2" ADAS_DRV
 SG_ FR_CMR_Obj_QualLvl06Sta : 152|7@1+ (1,0) [0|100] "%" ADAS_DRV
 SG_ FR_CMR_Obj_AlvAge06Val : 160|8@1+ (1,0) [0|255] "" ADAS_DRV
 SG_ FR_CMR_Obj_MvngFlag06Sta : 168|4@1+ (1,0) [0|9] "" ADAS_DRV
 SG_ FR_CMR_Obj_Id06Val : 172|7@1+ (1,0) [0|127] "" ADAS_DRV
 SG_ FR_CMR_Obj_Wth06Val : 180|7@1+ (0.05,0) [0|6.35] "m" ADAS_DRV
 SG_ FR_CMR_Obj_Clfct06Sta : 188|3@1+ (1,0) [0|6] "" ADAS_DRV
 SG_ FR_CMR_Obj_RelPosX06Val : 192|13@1+ (0.05,0) [0|350] "m" ADAS_DRV
 SG_ FR_CMR_Obj_RelPosY06Val : 206|12@1+ (0.05,-102.4) [-102.4|102.35] "m" ADAS_DRV
 SG_ FR_CMR_Obj_RelVelX06Val : 219|12@1+ (0.05,-100) [-100|100] "m/s" ADAS_DRV
 SG_ FR_CMR_Obj_RelVelY06Val : 232|10@1+ (0.05,-25) [-25|25] "m/s" ADAS_DRV
 SG_ FR_CMR_Obj_RelAccelX06Val : 243|9@1- (0.05,0) [-12.8|12.75] "m/s^2" ADAS_DRV

BO_ 387 L_FR_CMR_Obj_04_30ms: 32 FR_CMR
 SG_ FR_CMR_Obj_Crc04Val : 0|16@1+ (1,0) [0|65535] "" ADAS_DRV
 SG_ FR_CMR_Obj_AlvCnt04Val : 16|8@1+ (1,0) [0|255] "" ADAS_DRV
 SG_ FR_CMR_Obj_QualLvl07Sta : 24|7@1+ (1,0) [0|100] "%" ADAS_DRV
 SG_ FR_CMR_Obj_AlvAge07Val : 32|8@1+ (1,0) [0|255] "" ADAS_DRV
 SG_ FR_CMR_Obj_MvngFlag07Sta : 40|4@1+ (1,0) [0|9] "" ADAS_DRV
 SG_ FR_CMR_Obj_Id07Val : 44|7@1+ (1,0) [0|127] "" ADAS_DRV
 SG_ FR_CMR_Obj_Wth07Val : 52|7@1+ (0.05,0) [0|6.35] "m" ADAS_DRV
 SG_ FR_CMR_Obj_Clfct07Sta : 60|3@1+ (1,0) [0|6] "" ADAS_DRV
 SG_ FR_CMR_Obj_RelPosX07Val : 64|13@1+ (0.05,0) [0|350] "m" ADAS_DRV
 SG_ FR_CMR_Obj_RelPosY07Val : 78|12@1+ (0.05,-102.4) [-102.4|102.35] "m" ADAS_DRV
 SG_ FR_CMR_Obj_RelVelX07Val : 91|12@1+ (0.05,-100) [-100|100] "m/s" ADAS_DRV
 SG_ FR_CMR_Obj_RelVelY07Val : 104|10@1+ (0.05,-25) [-25|25] "m/s" ADAS_DRV
 SG_ FR_CMR_Obj_RelAccelX07Val : 115|9@1- (0.05,0) [-12.8|12.75] "m/s^2" ADAS_DRV
 SG_ FR_CMR_Obj_QualLvl08Sta : 152|7@1+ (1,0) [0|100] "%" ADAS_DRV
 SG_ FR_CMR_Obj_AlvAge08Val : 160|8@1+ (1,0) [0|255] "" ADAS_DRV
 SG_ FR_CMR_Obj_MvngFlag08Sta : 168|4@1+ (1,0) [0|9] "" ADAS_DRV
 SG_ FR_CMR_Obj_Id08Val : 172|7@1+ (1,0) [0|127] "" ADAS_DRV
 SG_ FR_CMR_Obj_Wth08Val : 180|7@1+ (0.05,0) [0|6.35] "m" ADAS_DRV
 SG_ FR_CMR_Obj_Clfct08Sta : 188|3@1+ (1,0) [0|6] "" ADAS_DRV
 SG_ FR_CMR_Obj_RelPosX08Val : 192|13@1+ (0.05,0) [0|350] "m" ADAS_DRV
 SG_ FR_CMR_Obj_RelPosY08Val : 206|12@1+ (0.05,-102.4) [-102.4|102.35] "m" ADAS_DRV
 SG_ FR_CMR_Obj_RelVelX08Val : 219|12@1+ (0.05,-100) [-100|100] "m/s" ADAS_DRV
 SG_ FR_CMR_Obj_RelVelY08Val : 232|10@1+ (0.05,-25) [-25|25] "m/s" ADAS_DRV
 SG_ FR_CMR_Obj_RelAccelX08Val : 243|9@1- (0.05,0) [-12.8|12.75] "m/s^2" ADAS_DRV

BO_ 388 L_FR_CMR_Obj_05_30ms: 32 FR_CMR
 SG_ FR_CMR_Obj_Crc05Val : 0|16@1+ (1,0) [0|65535] "" ADAS_DRV
 SG_ FR_CMR_Obj_AlvCnt05Val : 16|8@1+ (1,0) [0|255] "" ADAS_DRV
 SG_ FR_CMR_Obj_QualLvl09Sta : 24|7@1+ (1,0) [0|100] "%" ADAS_DRV
 SG_ FR_CMR_Obj_AlvAge09Val : 32|8@1+ (1,0) [0|255] "" ADAS_DRV
 SG_ FR_CMR_Obj_MvngFlag09Sta : 40|4@1+ (1,0) [0|9] "" ADAS_DRV
 SG_ FR_CMR_Obj_Id09Val : 44|7@1+ (1,0) [0|127] "" ADAS_DRV
 SG_ FR_CMR_Obj_Wth09Val : 52|7@1+ (0.05,0) [0|6.35] "m" ADAS_DRV
 SG_ FR_CMR_Obj_Clfct09Sta : 60|3@1+ (1,0) [0|6] "" ADAS_DRV
 SG_ FR_CMR_Obj_RelPosX09Val : 64|13@1+ (0.05,0) [0|350] "m" ADAS_DRV
 SG_ FR_CMR_Obj_RelPosY09Val : 78|12@1+ (0.05,-102.4) [-102.4|102.35] "m" ADAS_DRV
 SG_ FR_CMR_Obj_RelVelX09Val : 91|12@1+ (0.05,-100) [-100|100] "m/s" ADAS_DRV
 SG_ FR_CMR_Obj_RelVelY09Val : 104|10@1+ (0.05,-25) [-25|25] "m/s" ADAS_DRV
 SG_ FR_CMR_Obj_RelAccelX09Val : 115|9@1- (0.05,0) [-12.8|12.75] "m/s^2" ADAS_DRV
 SG_ FR_CMR_Obj_QualLvl10Sta : 152|7@1+ (1,0) [0|100] "%" ADAS_DRV
 SG_ FR_CMR_Obj_AlvAge10Val : 160|8@1+ (1,0) [0|255] "" ADAS_DRV
 SG_ FR_CMR_Obj_MvngFlag10Sta : 168|4@1+ (1,0) [0|9] "" ADAS_DRV
 SG_ FR_CMR_Obj_Id10Val : 172|7@1+ (1,0) [0|127] "" ADAS_DRV
 SG_ FR_CMR_Obj_Wth10Val : 180|7@1+ (0.05,0) [0|6.35] "m" ADAS_DRV
 SG_ FR_CMR_Obj_Clfct10Sta : 188|3@1+ (1,0) [0|6] "" ADAS_DRV
 SG_ FR_CMR_Obj_RelPosX10Val : 192|13@1+ (0.05,0) [0|350] "m" ADAS_DRV
 SG_ FR_CMR_Obj_RelPosY10Val : 206|12@1+ (0.05,-102.4) [-102.4|102.35] "m" ADAS_DRV
 SG_ FR_CMR_Obj_RelVelX10Val : 219|12@1+ (0.05,-100) [-100|100] "m/s" ADAS_DRV
 SG_ FR_CMR_Obj_RelVelY10Val : 232|10@1+ (0.05,-25) [-25|25] "m/s" ADAS_DRV
 SG_ FR_CMR_Obj_RelAccelX10Val : 243|9@1- (0.05,0) [-12.8|12.75] "m/s^2" ADAS_DRV

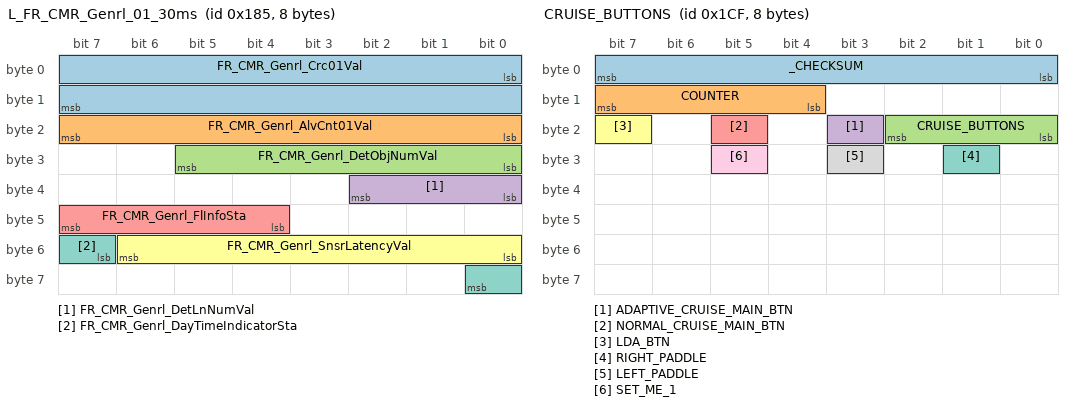
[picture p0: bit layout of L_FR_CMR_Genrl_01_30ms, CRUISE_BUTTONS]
BO_ 389 L_FR_CMR_Genrl_01_30ms: 8 FR_CMR
 SG_ FR_CMR_Genrl_Crc01Val : 0|16@1+ (1,0) [0|65535] "" ADAS_DRV
 SG_ FR_CMR_Genrl_AlvCnt01Val : 16|8@1+ (1,0) [0|255] "" ADAS_DRV
 SG_ FR_CMR_Genrl_DetObjNumVal : 24|6@1+ (1,0) [0|20] "" ADAS_DRV
 SG_ FR_CMR_Genrl_DetLnNumVal : 32|3@1+ (1,0) [0|4] "" ADAS_DRV
 SG_ FR_CMR_Genrl_FlInfoSta : 44|4@1+ (1,0) [0|2] "" ADAS_DRV
 SG_ FR_CMR_Genrl_SnsrLatencyVal : 48|7@1+ (10,0) [0|1270] "ms" ADAS_DRV
 SG_ FR_CMR_Genrl_DayTimeIndicatorSta : 55|2@1+ (1,0) [0|2] "" ADAS_DRV

BO_ 416 SCC_CONTROL: 32 ADRV
 SG_ CHECKSUM : 0|16@1+ (1,0) [0|65535] "" XXX
 SG_ COUNTER : 16|8@1+ (1,0) [0|255] "" XXX
 SG_ ACC_ObjDist : 24|11@1+ (0.1,0) [0|204.7] "m" XXX
 SG_ ACC_ObjRelSpd : 35|9@1+ (0.1,-16.4) [-16.4|34.7] "m/s" XXX
 SG_ SET_ME_3 : 45|2@0+ (1,0) [0|3] "" XXX
 SG_ ObjValid : 46|1@0+ (1,0) [0|3] "" XXX
 SG_ SET_ME_TMP_64 : 55|8@0+ (1,0) [0|63] "" XXX
 SG_ ZEROS_7 : 63|8@0+ (1,0) [0|255] "" XXX
 SG_ NEW_SIGNAL_1 : 64|2@1+ (1,0) [0|3] "" XXX
 SG_ MainMode_ACC : 66|1@1+ (1,0) [0|1] "" XXX
 SG_ ACCMode : 68|3@1+ (1,0) [0|7] "" XXX
 SG_ ZEROS_9 : 71|5@1+ (1,0) [0|15] "" XXX
 SG_ CRUISE_STANDSTILL : 76|1@1+ (1,0) [0|1] "" XXX
 SG_ ZEROS_5 : 77|11@1+ (1,0) [0|2047] "" XXX
 SG_ DISTANCE_SETTING : 88|3@1+ (1,0) [0|3] "" XXX
 SG_ ZEROS_8 : 95|5@0+ (1,0) [0|31] "" XXX
 SG_ VSetDis : 103|8@0+ (1,0) [0|255] "km/h or mph" XXX
 SG_ NEW_SIGNAL_6 : 104|1@0+ (1,0) [0|1] "" XXX
 SG_ SET_ME_2 : 105|3@1+ (1,0) [0|7] "" XXX
 SG_ NEW_SIGNAL_3 : 109|2@0+ (1,0) [0|1] "" XXX
 SG_ ZEROS_10 : 111|2@0+ (1,0) [0|3] "" XXX
 SG_ ZEROS_6 : 119|16@0+ (1,0) [0|65535] "" XXX
 SG_ aReqValue : 128|11@1+ (0.01,-10.23) [-10.23|10.24] "m/s^2" XXX
 SG_ aReqRaw : 140|11@1+ (0.01,-10.23) [-10.23|10.24] "m/s^2" XXX
 SG_ JerkUpperLimit : 158|7@0+ (0.1,0) [0|0] "" XXX
 SG_ JerkLowerLimit : 166|7@0+ (0.1,0) [0|12.7] "m/s^3" XXX
 SG_ NEW_SIGNAL_2 : 168|2@1+ (1,0) [0|3] "" XXX
 SG_ NEW_SIGNAL_8 : 170|4@1+ (1,0) [0|15] "" XXX
 SG_ OBJ_STATUS : 176|3@1+ (1,0) [0|7] "" XXX
 SG_ ZEROS_4 : 183|4@0+ (1,0) [0|63] "" XXX
 SG_ StopReq : 184|1@0+ (1,0) [0|1] "" XXX
 SG_ ZEROS_3 : 191|7@0+ (1,0) [0|127] "" XXX
 SG_ NEW_SIGNAL_15 : 192|11@1+ (0.1,0) [0|204.7] "m" XXX
 SG_ ZEROS_2 : 207|5@0+ (1,0) [0|63] "" XXX
 SG_ ZEROS : 215|48@0+ (1,0) [0|281474976710655] "" XXX

BO_ 426 CRUISE_BUTTONS_ALT: 16 XXX
 SG_ CHECKSUM : 0|16@1+ (1,0) [0|65535] "" XXX
 SG_ COUNTER : 16|8@1+ (1,0) [0|255] "" XXX
 SG_ NEW_SIGNAL_1 : 24|4@1+ (1,0) [0|15] "" XXX
 SG_ SET_ME_1 : 28|2@1+ (1,0) [0|3] "" XXX
 SG_ DISTANCE_UNIT : 30|1@1+ (1,0) [0|1] "" XXX
 SG_ NEW_SIGNAL_2 : 31|3@1+ (1,0) [0|7] "" XXX
 SG_ ADAPTIVE_CRUISE_MAIN_BTN : 34|1@1+ (1,0) [0|1] "" XXX
 SG_ NEW_SIGNAL_3 : 35|1@1+ (1,0) [0|1] "" XXX
 SG_ CRUISE_BUTTONS : 36|3@1+ (1,0) [0|4] "" XXX
 SG_ LDA_BTN : 39|1@1+ (1,0) [0|1] "" XXX
 SG_ NEW_SIGNAL_4 : 40|1@1+ (1,0) [0|1] "" XXX
 SG_ NORMAL_CRUISE_MAIN_BTN : 41|1@1+ (1,0) [0|1] "" XXX
 SG_ NEW_SIGNAL_5 : 42|2@1+ (1,0) [0|3] "" XXX
 SG_ SET_ME_2 : 44|3@1+ (1,0) [0|7] "" XXX
 SG_ NEW_SIGNAL_6 : 47|1@1+ (1,0) [0|1] "" XXX
 SG_ BYTE6 : 48|8@1+ (1,0) [0|255] "" XXX
 SG_ BYTE7 : 56|8@1+ (1,0) [0|255] "" XXX
 SG_ BYTE8 : 64|8@1+ (1,0) [0|255] "" XXX
 SG_ BYTE9 : 72|8@1+ (1,0) [0|255] "" XXX
 SG_ BYTE10 : 80|8@1+ (1,0) [0|255] "" XXX
 SG_ BYTE11 : 88|8@1+ (1,0) [0|255] "" XXX
 SG_ BYTE12 : 96|8@1+ (1,0) [0|255] "" XXX
 SG_ BYTE13 : 104|8@1+ (1,0) [0|255] "" XXX
 SG_ BYTE14 : 112|8@1+ (1,0) [0|255] "" XXX
 SG_ BYTE15 : 120|8@1+ (1,0) [0|255] "" XXX

BO_ 437 FR_CMR_03_50ms: 32 FR_CMR
 SG_ FR_CMR_Crc3Val : 0|16@1+ (1,0) [0|65535] "" RR_C_RDR,CGW
 SG_ FR_CMR_AlvCnt3Val : 16|8@1+ (1,0) [0|255] "" RR_C_RDR,CGW
 SG_ Info_LftLnQualSta : 24|3@1+ (1,0) [0|7] "" RR_C_RDR,CGW
 SG_ Info_LftLnDptSta : 27|2@1+ (1,0) [0|3] "" RR_C_RDR,CGW
 SG_ Info_LftLnPosVal : 29|14@1- (0.0039625,0) [-32.4608|32.4568375] "m" RR_C_RDR,CGW
 SG_ Info_LftLnHdingAnglVal : 43|10@1- (0.000976563,0) [-0.500000256|0.499023693] "rad" RR_C_RDR,CGW
 SG_ Info_LftLnCvtrVal : 64|16@1- (1e-06,0) [-0.032768|0.032767] "1/m" CGW
 SG_ Info_LftLnCrvtrDrvtvVal : 80|16@1- (4e-09,0) [-0.000131072|0.000131068] "1/m2" CGW
 SG_ Info_RtLnQualSta : 96|3@1+ (1,0) [0|7] "" RR_C_RDR,CGW
 SG_ Info_RtLnDptSta : 99|2@1+ (1,0) [0|3] "" RR_C_RDR,CGW
 SG_ Info_RtLnPosVal : 101|14@1- (0.0039625,0) [-32.4608|32.4568375] "m" RR_C_RDR,CGW
 SG_ Info_RtLnHdingAnglVal : 115|10@1- (0.000976563,0) [-0.500000256|0.499023693] "rad" RR_C_RDR,CGW
 SG_ Info_RtLnCvtrVal : 128|16@1- (1e-06,0) [-0.032768|0.032767] "1/m" CGW
 SG_ Info_RtLnCrvtrDrvtvVal : 144|16@1- (4e-09,0) [-0.000131072|0.000131068] "1/m2" CGW
 SG_ ID_CIPV : 192|7@1+ (1,0) [0|127] "" Dummy
 SG_ Relative_Velocity : 200|12@1+ (0.05,-100) [-100|104.75] "m/s" Dummy
 SG_ Longitudinal_Distance : 212|12@1+ (0.05,0) [0|204.75] "m" Dummy

BO_ 442 BLINDSPOTS_REAR_CORNERS: 24 XXX
 SG_ CHECKSUM : 0|16@1+ (1,0) [0|65535] "" XXX
 SG_ COUNTER : 16|8@1+ (1,0) [0|255] "" XXX
 SG_ LEFT_BLOCKED : 24|1@0+ (1,0) [0|1] "" XXX
 SG_ LEFT_MB : 30|1@0+ (1,0) [0|3] "" XXX
 SG_ MORE_LEFT_PROB : 32|1@1+ (1,0) [0|3] "" XXX
 SG_ FL_INDICATOR : 46|6@0+ (1,0) [0|1] "" XXX
 SG_ FR_INDICATOR : 54|6@0+ (1,0) [0|63] "" XXX
 SG_ RIGHT_BLOCKED : 64|1@0+ (1,0) [0|1] "" XXX
 SG_ COLLISION_AVOIDANCE_ACTIVE : 68|1@0+ (1,0) [0|1] "" XXX
 SG_ NEW_SIGNAL_2 : 96|1@0+ (1,0) [0|1] "" XXX
 SG_ FL_INDICATOR_ALT : 138|1@0+ (1,0) [0|1] "" XXX
 SG_ FR_INDICATOR_ALT : 141|1@0+ (1,0) [0|1] "" XXX

BO_ 463 CRUISE_BUTTONS: 8 XXX
 SG_ _CHECKSUM : 0|8@1+ (1,0) [0|65535] "" XXX
 SG_ COUNTER : 12|4@1+ (1,0) [0|255] "" XXX
 SG_ CRUISE_BUTTONS : 16|3@1+ (1,0) [0|3] "" XXX
 SG_ ADAPTIVE_CRUISE_MAIN_BTN : 19|1@1+ (1,0) [0|1] "" XXX
 SG_ NORMAL_CRUISE_MAIN_BTN : 21|1@1+ (1,0) [0|1] "" XXX
 SG_ LDA_BTN : 23|1@1+ (1,0) [0|1] "" XXX
 SG_ RIGHT_PADDLE : 25|1@1+ (1,0) [0|1] "" XXX
 SG_ LEFT_PADDLE : 27|1@1+ (1,0) [0|1] "" XXX
 SG_ SET_ME_1 : 29|1@1+ (1,0) [0|1] "" XXX

BO_ 474 ADRV_0x1da: 32 ADRV
 SG_ CHECKSUM : 0|16@1+ (1,0) [0|65535] "" XXX
 SG_ COUNTER : 16|8@1+ (1,0) [0|255] "" XXX
 SG_ SET_ME_22 : 31|8@0+ (1,0) [0|255] "" XXX
 SG_ SET_ME_41 : 47|8@0+ (1,0) [0|255] "" XXX

BO_ 480 LFAHDA_CLUSTER: 16 ADRV
 SG_ CHECKSUM : 0|16@1+ (1,0) [0|65535] "" XXX
 SG_ COUNTER : 16|8@1+ (1,0) [0|255] "" XXX
 SG_ NEW_SIGNAL_4 : 24|1@0+ (1,0) [0|1] "" XXX
 SG_ NEW_SIGNAL_5 : 25|1@0+ (1,0) [0|1] "" XXX
 SG_ NEW_SIGNAL_2 : 30|1@0+ (1,0) [0|1] "" XXX
 SG_ HDA_ICON : 31|1@1+ (1,0) [0|1] "" XXX
 SG_ NEW_SIGNAL_1 : 32|3@1+ (1,0) [0|7] "" XXX
 SG_ LFA_ICON : 47|2@1+ (1,0) [0|3] "" XXX
 SG_ NEW_SIGNAL_3 : 49|1@0+ (1,0) [0|1] "" XXX

BO_ 485 BLINDSPOTS_FRONT_CORNER_1: 16 XXX
 SG_ CHECKSUM : 0|16@1+ (1,0) [0|65535] "" XXX
 SG_ COUNTER : 16|8@1+ (1,0) [0|255] "" XXX
 SG_ REVERSING : 24|1@0+ (1,0) [0|1] "" XXX
 SG_ NEW_SIGNAL_5 : 31|2@0+ (1,0) [0|3] "" XXX
 SG_ NEW_SIGNAL_7 : 32|2@1+ (1,0) [0|3] "" XXX
 SG_ NEW_SIGNAL_8 : 47|8@0+ (1,0) [0|255] "" XXX
 SG_ NEW_SIGNAL_9 : 55|8@0+ (1,0) [0|255] "" XXX
 SG_ NEW_SIGNAL_4 : 80|1@0+ (1,0) [0|1] "" XXX
 SG_ NEW_SIGNAL_3 : 88|1@0+ (1,0) [0|1] "" XXX
 SG_ NEW_SIGNAL_2 : 96|1@0+ (1,0) [0|1] "" XXX
 SG_ NEW_SIGNAL_1 : 108|2@0+ (1,0) [0|3] "" XXX

BO_ 490 ADRV_0x1ea: 32 ADRV
 SG_ CHECKSUM : 0|16@1+ (1,0) [0|65535] "" XXX
 SG_ COUNTER : 16|8@1+ (1,0) [0|255] "" XXX
 SG_ SET_ME_1C : 31|8@0+ (1,0) [0|255] "" XXX
 SG_ NEW_SIGNAL_1 : 32|2@1+ (1,0) [0|3] "" XXX
 SG_ NEW_SIGNAL_2 : 47|2@0+ (1,0) [0|3] "" XXX
 SG_ NEW_SIGNAL_3 : 55|8@0+ (1,0) [0|255] "" XXX
 SG_ NEW_SIGNAL_4 : 64|6@1+ (1,0) [0|31] "" XXX
 SG_ NEW_SIGNAL_5 : 72|2@1+ (1,0) [0|3] "" XXX
 SG_ NEW_SIGNAL_6 : 75|5@1+ (1,0) [0|31] "" XXX
 SG_ NEW_SIGNAL_7 : 80|5@1+ (1,0) [0|31] "" XXX
 SG_ NEW_SIGNAL_8 : 88|7@1+ (1,0) [0|127] "" XXX
 SG_ NEW_SIGNAL_9 : 96|1@0+ (1,0) [0|1] "" XXX
 SG_ SET_ME_FF : 120|8@1+ (1,0) [0|255] "" XXX
 SG_ NEW_SIGNAL_10 : 143|5@0+ (1,0) [0|31] "" XXX
 SG_ NEW_SIGNAL_11 : 144|3@1+ (1,0) [0|7] "" XXX
 SG_ NEW_SIGNAL_12 : 152|6@1+ (1,0) [0|63] "" XXX
 SG_ NEW_SIGNAL_13 : 160|1@0+ (1,0) [0|1] "" XXX
 SG_ NEW_SIGNAL_14 : 163|5@1+ (1,0) [0|31] "" XXX
 SG_ NEW_SIGNAL_16 : 168|3@1+ (1,0) [0|7] "" XXX
 SG_ NEW_SIGNAL_15 : 175|4@0+ (1,0) [0|63] "" XXX
 SG_ NEW_SIGNAL_17 : 176|2@1+ (1,0) [0|3] "" XXX
 SG_ NEW_SIGNAL_18 : 184|1@0+ (1,0) [0|1] "" XXX
 SG_ NEW_SIGNAL_19 : 208|3@1+ (1,0) [0|7] "" XXX
 SG_ NEW_SIGNAL_20 : 212|1@0+ (1,0) [0|1] "" XXX
 SG_ SET_ME_TMP_F : 232|5@1+ (1,0) [0|31] "" XXX
 SG_ SET_ME_TMP_F_2 : 240|5@1+ (1,0) [0|31] "" XXX

BO_ 506 CLUSTER_SPEED_LIMIT: 32 XXX
 SG_ SPEED_LIMIT_1 : 39|7@0+ (1,0) [0|255] "" XXX
 SG_ SPEED_LIMIT_2 : 47|7@0+ (1,0) [0|255] "" XXX
 SG_ SECONDARY_LIMIT_1 : 79|8@0+ (1,0) [0|127] "" XXX
 SG_ SECONDARY_LIMIT_2 : 103|8@0+ (1,0) [0|127] "" XXX
 SG_ SPEED_LIMIT_3 : 119|8@0+ (1,0) [0|255] "" XXX
 SG_ ARROW_DOWN : 120|1@0+ (1,0) [0|1] "" XXX
 SG_ ARROW_UP : 121|1@0+ (1,0) [0|1] "" XXX
 SG_ CHIME_2 : 122|2@1+ (1,0) [0|7] "" XXX
 SG_ SPEED_CHANGE_BLINKING : 129|1@1+ (1,0) [0|3] "" XXX
 SG_ CHIME_1 : 133|1@0+ (1,0) [0|1] "" XXX
 SG_ SCHOOL_ZONE : 155|1@0+ (1,0) [0|1] "" XXX

BO_ 507 CAM_0x1fb: 32 CAMERA
 SG_ CHECKSUM : 0|16@1+ (1,0) [0|65535] "" XXX
 SG_ COUNTER : 16|8@1+ (1,0) [0|255] "" XXX

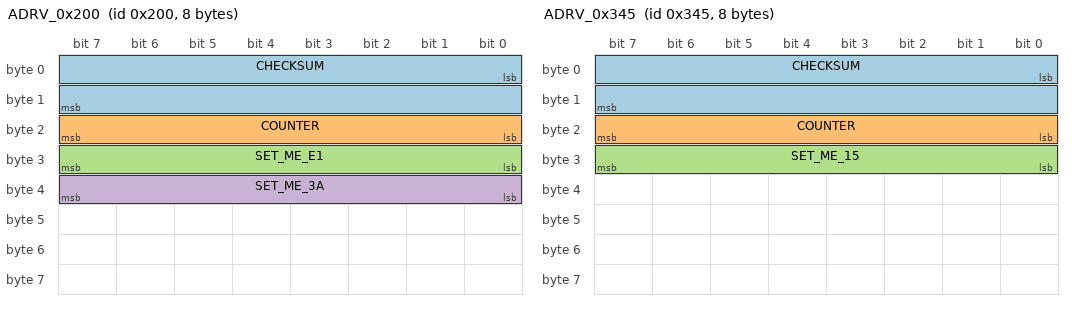
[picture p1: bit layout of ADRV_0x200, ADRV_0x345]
BO_ 512 ADRV_0x200: 8 ADRV
 SG_ CHECKSUM : 0|16@1+ (1,0) [0|65535] "" XXX
 SG_ COUNTER : 16|8@1+ (1,0) [0|255] "" XXX
 SG_ SET_ME_E1 : 24|8@1+ (1,0) [0|255] "" XXX
 SG_ SET_ME_3A : 32|8@1+ (1,0) [0|255] "" XXX

BO_ 593 RADAR_0x251: 16 FRONT_RADAR
 SG_ CHECKSUM : 0|16@1+ (1,0) [0|65535] "" XXX
 SG_ COUNTER : 16|8@1+ (1,0) [0|255] "" XXX

BO_ 736 MANUAL_SPEED_LIMIT_ASSIST: 32 XXX
 SG_ CHECKSUM : 0|16@1+ (1,0) [0|65535] "" XXX
 SG_ COUNTER : 16|8@1+ (1,0) [0|255] "" XXX
 SG_ MSLA_STATUS : 26|2@1+ (1,0) [0|3] "" XXX
 SG_ MSLA_ENABLED : 38|1@1+ (1,0) [0|1] "" XXX
 SG_ MAX_SPEED : 55|8@0+ (1,0) [0|255] "" XXX
 SG_ MAX_SPEED_COPY : 144|8@1+ (1,0) [0|255] "" XXX

BO_ 837 ADRV_0x345: 8 ADRV
 SG_ CHECKSUM : 0|16@1+ (1,0) [0|65535] "" XXX
 SG_ COUNTER : 16|8@1+ (1,0) [0|255] "" XXX
 SG_ SET_ME_15 : 24|8@1+ (1,0) [0|255] "" XXX

BO_ 866 CAM_0x362: 32 CAMERA
 SG_ CHECKSUM : 0|16@1+ (1,0) [0|65535] "" XXX
 SG_ COUNTER : 16|8@1+ (1,0) [0|255] "" XXX
 SG_ BYTE3 : 24|8@1+ (1,0) [0|255] "" XXX
 SG_ BYTE4 : 32|8@1+ (1,0) [0|255] "" XXX
 SG_ BYTE5 : 40|8@1+ (1,0) [0|255] "" XXX
 SG_ BYTE6 : 48|8@1+ (1,0) [0|255] "" XXX
 SG_ LEFT_LANE_LINE : 56|2@1+ (1,0) [0|3] "" XXX
 SG_ SET_ME_0 : 58|2@1+ (1,0) [0|3] "" XXX
 SG_ RIGHT_LANE_LINE : 60|2@1+ (1,0) [0|3] "" XXX
 SG_ SET_ME_0_2 : 62|2@1+ (1,0) [0|3] "" XXX
 SG_ BYTE8 : 64|8@1+ (1,0) [0|255] "" XXX
 SG_ BYTE9 : 72|8@1+ (1,0) [0|255] "" XXX
 SG_ BYTE10 : 80|8@1+ (1,0) [0|255] "" XXX
 SG_ BYTE11 : 88|8@1+ (1,0) [0|255] "" XXX
 SG_ BYTE12 : 96|8@1+ (1,0) [0|255] "" XXX
 SG_ BYTE13 : 104|8@1+ (1,0) [0|255] "" XXX
 SG_ BYTE14 : 112|8@1+ (1,0) [0|255] "" XXX
 SG_ BYTE15 : 120|8@1+ (1,0) [0|255] "" XXX
 SG_ BYTE16 : 128|8@1+ (1,0) [0|255] "" XXX
 SG_ BYTE17 : 136|8@1+ (1,0) [0|255] "" XXX
 SG_ BYTE18 : 144|8@1+ (1,0) [0|255] "" XXX
 SG_ BYTE19 : 152|8@1+ (1,0) [0|255] "" XXX
 SG_ BYTE20 : 160|8@1+ (1,0) [0|255] "" XXX
 SG_ BYTE21 : 168|8@1+ (1,0) [0|255] "" XXX
 SG_ BYTE22 : 176|8@1+ (1,0) [0|255] "" XXX
 SG_ BYTE23 : 184|8@1+ (1,0) [0|255] "" XXX
 SG_ BYTE24 : 192|8@1+ (1,0) [0|255] "" XXX
 SG_ BYTE25 : 200|8@1+ (1,0) [0|255] "" XXX
 SG_ BYTE26 : 208|8@1+ (1,0) [0|255] "" XXX
 SG_ BYTE27 : 216|8@1+ (1,0) [0|255] "" XXX
 SG_ BYTE28 : 224|8@1+ (1,0) [0|255] "" XXX
 SG_ BYTE29 : 232|8@1+ (1,0) [0|255] "" XXX
 SG_ BYTE30 : 240|8@1+ (1,0) [0|255] "" XXX
 SG_ BYTE31 : 248|8@1+ (1,0) [0|255] "" XXX

BO_ 874 BLINDSPOTS_FRONT_CORNER_2: 16 XXX
 SG_ CHECKSUM : 0|16@1+ (1,0) [0|65535] "" XXX
 SG_ COUNTER : 16|8@1+ (1,0) [0|255] "" XXX

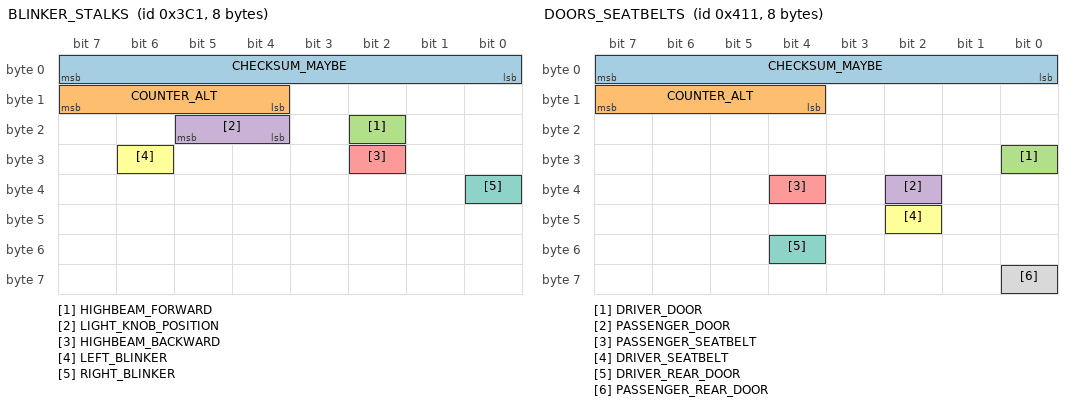
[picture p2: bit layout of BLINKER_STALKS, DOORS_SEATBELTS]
BO_ 961 BLINKER_STALKS: 8 XXX
 SG_ CHECKSUM_MAYBE : 7|8@0+ (1,0) [0|255] "" XXX
 SG_ COUNTER_ALT : 15|4@0+ (1,0) [0|15] "" XXX
 SG_ HIGHBEAM_FORWARD : 18|1@0+ (1,0) [0|1] "" XXX
 SG_ LIGHT_KNOB_POSITION : 21|2@0+ (1,0) [0|3] "" XXX
 SG_ HIGHBEAM_BACKWARD : 26|1@0+ (1,0) [0|1] "" XXX
 SG_ LEFT_BLINKER : 30|1@0+ (1,0) [0|1] "" XXX
 SG_ RIGHT_BLINKER : 32|1@0+ (1,0) [0|1] "" XXX

BO_ 1041 DOORS_SEATBELTS: 8 XXX
 SG_ CHECKSUM_MAYBE : 7|8@0+ (1,0) [0|65535] "" XXX
 SG_ COUNTER_ALT : 15|4@0+ (1,0) [0|15] "" XXX
 SG_ DRIVER_DOOR : 24|1@1+ (1,0) [0|1] "" XXX
 SG_ PASSENGER_DOOR : 34|1@0+ (1,0) [0|1] "" XXX
 SG_ PASSENGER_SEATBELT : 36|1@0+ (1,0) [0|1] "" XXX
 SG_ DRIVER_SEATBELT : 42|1@0+ (1,0) [0|1] "" XXX
 SG_ DRIVER_REAR_DOOR : 52|1@0+ (1,0) [0|1] "" XXX
 SG_ PASSENGER_REAR_DOOR : 56|1@0+ (1,0) [0|1] "" XXX

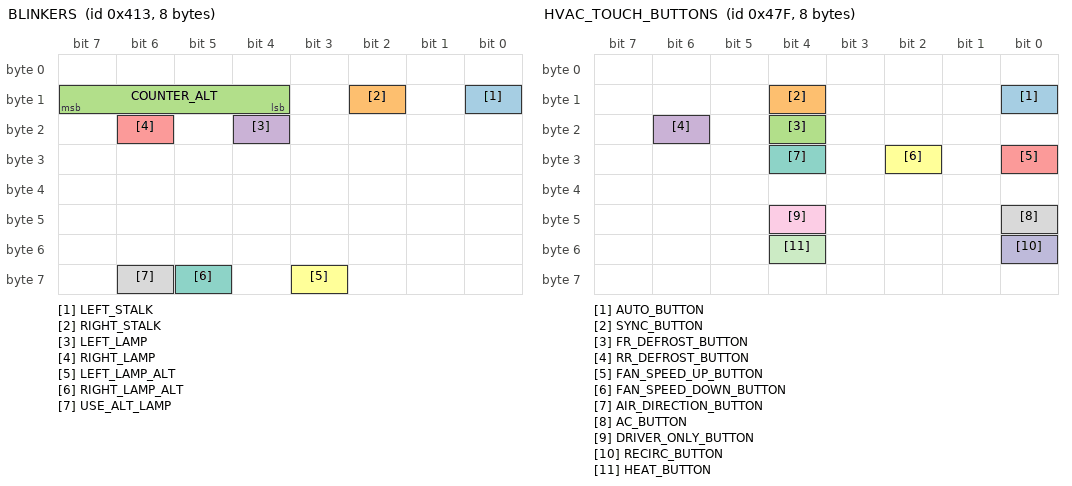
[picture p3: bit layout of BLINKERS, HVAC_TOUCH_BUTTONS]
BO_ 1043 BLINKERS: 8 XXX
 SG_ LEFT_STALK : 8|1@0+ (1,0) [0|1] "" XXX
 SG_ RIGHT_STALK : 10|1@0+ (1,0) [0|1] "" XXX
 SG_ COUNTER_ALT : 15|4@0+ (1,0) [0|15] "" XXX
 SG_ LEFT_LAMP : 20|1@0+ (1,0) [0|1] "" XXX
 SG_ RIGHT_LAMP : 22|1@0+ (1,0) [0|1] "" XXX
 SG_ LEFT_LAMP_ALT : 59|1@0+ (1,0) [0|1] "" XXX
 SG_ RIGHT_LAMP_ALT : 61|1@0+ (1,0) [0|1] "" XXX
 SG_ USE_ALT_LAMP : 62|1@0+ (1,0) [0|1] "" XXX

BO_ 1144 DRIVE_MODE: 8 XXX
 SG_ DRIVE_MODE : 0|16@1+ (1,-61611) [0|61611] "" XXX
 SG_ DRIVE_MODE2 : 28|3@1+ (1,0) [1|3] "" XXX

BO_ 1151 HVAC_TOUCH_BUTTONS: 8 XXX
 SG_ AUTO_BUTTON : 8|1@0+ (1,0) [0|1] "" XXX
 SG_ SYNC_BUTTON : 12|1@0+ (1,0) [0|1] "" XXX
 SG_ FR_DEFROST_BUTTON : 20|1@0+ (1,0) [0|1] "" XXX
 SG_ RR_DEFROST_BUTTON : 22|1@0+ (1,0) [0|1] "" XXX
 SG_ FAN_SPEED_UP_BUTTON : 24|1@0+ (1,0) [0|1] "" XXX
 SG_ FAN_SPEED_DOWN_BUTTON : 26|1@0+ (1,0) [0|1] "" XXX
 SG_ AIR_DIRECTION_BUTTON : 28|1@0+ (1,0) [0|1] "" XXX
 SG_ AC_BUTTON : 40|1@0+ (1,0) [0|1] "" XXX
 SG_ DRIVER_ONLY_BUTTON : 44|1@0+ (1,0) [0|1] "" XXX
 SG_ RECIRC_BUTTON : 48|1@0+ (1,0) [0|1] "" XXX
 SG_ HEAT_BUTTON : 52|1@0+ (1,0) [0|1] "" XXX

BO_ 1240 CLUSTER_INFO: 8 XXX
 SG_ DISTANCE_UNIT : 0|1@1+ (1,0) [0|1] "" XXX

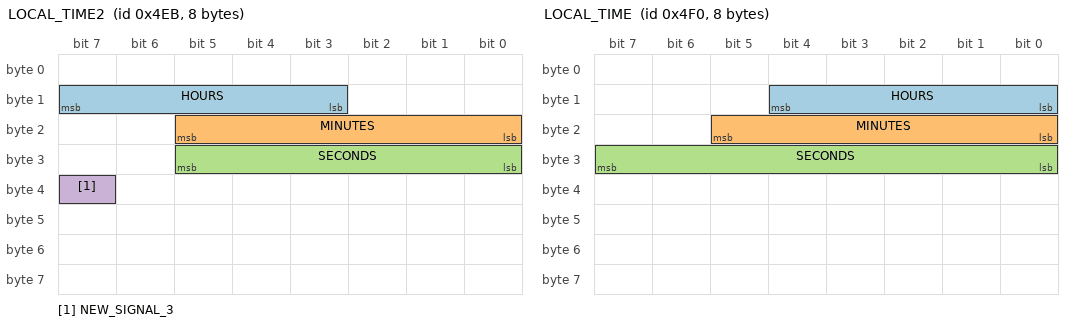
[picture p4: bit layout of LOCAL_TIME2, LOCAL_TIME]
BO_ 1259 LOCAL_TIME2: 8 XXX
 SG_ HOURS : 15|5@0+ (1,0) [0|31] "" XXX
 SG_ MINUTES : 21|6@0+ (1,0) [0|63] "" XXX
 SG_ SECONDS : 24|6@1+ (1,0) [0|63] "" XXX
 SG_ NEW_SIGNAL_3 : 39|1@0+ (1,0) [0|1] "" XXX

BO_ 1264 LOCAL_TIME: 8 XXX
 SG_ HOURS : 12|5@0+ (1,0) [0|31] "" XXX
 SG_ MINUTES : 21|6@0+ (1,0) [0|63] "" XXX
 SG_ SECONDS : 31|8@0+ (1,0) [0|59] "" XXX

CM_ BO_ 74 "[P] Periodic";
CM_ SG_ 74 IMU_Crc1Val "IMU_CyclicRedundancyCheck1Value";
CM_ SG_ 74 IMU_AlvCnt1Val "IMU_AliveCounter1Value";
CM_ SG_ 74 IMU_YawSigSta "This signal indicates the failure status of the yaw rate signal and its sensing element using a 4-bit value, where 0000B means no failure, xxx1B indicates a yaw rate failure, xx1xB signals that initialization is running, and x1xxB and 1xxxB are reserved.";
CM_ SG_ 74 IMU_LatAccelSigSta "This signal represents the failure status of the lateral acceleration signal and sensing element using a 4-bit value, where 0000B means no failure, xxx1B indicates a lateral acceleration failure, xx1xB shows initialization is in progress, and x1xxB and 1xxxB are reserved.";
CM_ SG_ 74 IMU_YawRtVal "IThis signal encodes yaw rate from -163.84 to +163.83 ˚/s using a 16-bit value (0x0000 to 0xFFFE), where physical value = raw * 0.005 - 163.84.";
CM_ SG_ 74 IMU_LatAccelVal "This signal encodes lateral acceleration from -4.1768g to +4.1765g using a 16-bit value (0x0000 to 0xFFFE), where physical value = raw * 0.000127465 - 4.17677312.";
CM_ SG_ 96 BRAKE_PRESSURE "User applied brake pedal pressure. Ramps from computer applied pressure on falling edge of cruise. Cruise cancels if !=0";
CM_ SG_ 101 BRAKE_POSITION "User applied brake pedal position, max is ~700. Signed on some vehicles";
CM_ BO_ 160 "[P] Periodic";
CM_ SG_ 160 WHL_Crc1Val "WHL_CyclicRedundancyCheck1Value";
CM_ SG_ 160 WHL_AlvCnt1Val "WHL_AliveCounter1Value";
CM_ SG_ 160 WHL_PlsFLVal "This signal indicates accumulated pulse counter of ABS^ESC wheel speed sensor (FL^FR^RL^RR)
Receiver unit uses this signal for calculation of vehicle movement distance.
Requested resolution of this signal is 0.5 pulses and refer to below (wheel sensor signal).";
CM_ SG_ 160 WHL_PlsFRVal "This signal indicates accumulated pulse counter of ABS^ESC wheel speed sensor (FL^FR^RL^RR)
Receiver unit uses this signal for calculation of vehicle movement distance.
Requested resolution of this signal is 0.5 pulses and refer to below (wheel sensor signal).";
CM_ SG_ 160 WHL_PlsRLVal "This signal indicates accumulated pulse counter of ABS^ESC wheel speed sensor (FL^FR^RL^RR)
Receiver unit uses this signal for calculation of vehicle movement distance.
Requested resolution of this signal is 0.5 pulses and refer to below (wheel sensor signal).";
CM_ SG_ 160 WHL_PlsRRVal "This signal indicates accumulated pulse counter of ABS^ESC wheel speed sensor (FL^FR^RL^RR)
Receiver unit uses this signal for calculation of vehicle movement distance.
Requested resolution of this signal is 0.5 pulses and refer to below (wheel sensor signal).";
CM_ SG_ 160 WHL_SpdFLVal "WHL_SpeedFrontLeftValue ##2G##ESC - WHL_SPD11 - WHL_SPD_FL";
CM_ SG_ 160 WHL_SpdFRVal "WHL_SpeedFrontRightValue ##2G##ESC - WHL_SPD11 - WHL_SPD_FR";
CM_ SG_ 160 WHL_SpdRLVal "WHL_SpeedRearLeftValue ##2G##ESC - WHL_SPD11 - WHL_SPD_RL";
CM_ SG_ 160 WHL_SpdRRVal "WHL_SpeedRearRightValue ##2G##ESC - WHL_SPD11 - WHL_SPD_RR";
CM_ SG_ 203 ADAS_CMD_Crc35Val "ADAS_CMD_CyclicRedundancyCheck35Value";
CM_ SG_ 203 ADAS_CMD_AlvCnt35Val "ADAS_CMD_AliveCounter35Value";
CM_ SG_ 203 ADAS_ActvACISta "ADAS Active AngleControlInterface State";
CM_ SG_ 203 ADAS_ActvACILvl2Sta "ADAS Active AngleControlInterface Level 2 State";
CM_ SG_ 203 ADAS_StrAnglReqVal "ADAS Steering Angle Request Value";
CM_ SG_ 203 ADAS_ACIAnglTqRedcGainVal "ADAS AngleControlInterface Angle Torque Reduction Gain Value";
CM_ SG_ 203 FCA_ESA_ActvSta "FCA_ESA Active State";
CM_ SG_ 203 FCA_ESA_TqBstGainVal "FCA_ESA Torque Boost Gain Value";
CM_ BO_ 234 "[P] Periodic";
CM_ SG_ 234 MDPS_Crc1Val "MDPS_CyclicRedundancyCheck1Value ##2G##MDPS - MDPS11 - CF_Mdps_Chksum";
CM_ SG_ 234 MDPS_AlvCnt1Val "MDPS_AliveCounter1Value ##2G##MDPS - MDPS11 - CF_Mdps_AliveCnt";
CM_ SG_ 234 MDPS_WrngLmpSta "MDPS_WarningLampStatus ##2G##MDPS - MDPS11 - CF_Mdps_WLmp";
CM_ SG_ 234 MDPS_Typ "MDPS_Type ##2G##MDPS - MDPS11 - CF_Mdps_Type";
CM_ SG_ 234 MDPS_EngIdleRpmReq "MDPS_EngineIdleRpmRequest ##2G##MDPS - MDPS11 - CF_Mdps_ALTRequest";
CM_ SG_ 234 MDPS_VsmPlgInSta "MDPS_VsmPluginStatus ##2G##MDPS - MDPS11 - CF_Mdps_VSM_FUNC";
CM_ SG_ 234 MDPS_VsmDfctvSta "MDPS_VsmDefectiveStatus ##2G##MDPS - MDPS12 - CF_Mdps_Def";
CM_ SG_ 234 MDPS_VsmSigErrSta "MDPS_VsmSignalErrorStatus ##2G##MDPS - MDPS12 - CF_Mdps_SErr";
CM_ SG_ 234 MDPS_PaPlugInSta "MDPS_PaPlugInStatus ##2G##MDPS - MDPS11 - CF_Mdps_PA_FUNC";
CM_ SG_ 234 MDPS_PaModeSta "MDPS_PaModeStatus ##2G##MDPS - MDPS11 - CF_Mdps_Stat";
CM_ SG_ 234 MDPS_PaCanfltSta "MDPS_PaCanFaultStatus ##2G##MDPS - MDPS11 - CF_MDPS_PACanfailflag";
CM_ SG_ 234 MDPS_LkaPlgInSta "MDPS_LkaPlug-inStatus ##2G##MDPS - MDPS11 - CF_Mdps_LKA_FUNC";
CM_ SG_ 234 MDPS_LkaToiActvSta "MDPS_LkaToiActiveStatus ##2G##MDPS - MDPS12 - CF_Mdps_ToiActive";
CM_ SG_ 234 MDPS_LkaToiUnblSta "MDPS_LkaToiUnavailableStatus ##2G##MDPS - MDPS12 - CF_Mdps_ToiUnavail";
CM_ SG_ 234 MDPS_LkaToiFltSta "MDPS_LkaToiFaultStatus ##2G##MDPS - MDPS12 - CF_Mdps_ToiFlt";
CM_ SG_ 234 MDPS_LkaFailSta "MDPS_LkaFailStatus ##2G##MDPS - MDPS12 - CF_Mdps_FailStat";
CM_ SG_ 234 MDPS_ResetOpSta "0x0 Normal 0x1 Reset Complete 0x2 Reset Fail 0x3 Reserved";
CM_ SG_ 234 MDPS_CurrModVal "MDPS_CurrentModeStatus ##2G##MDPS - MDPS11 - CF_Mdps_CurrMode";
CM_ SG_ 234 MDPS_OutTqVal "MDPS column torque this signal has direction information. '+' Value means Counter clock wise rotation. '-' value means Clock wise rotation.";
CM_ SG_ 234 MDPS_VsmActResp "Information of VSM Tqrque Intervention Act Response";
CM_ SG_ 234 Reprogram_State_MDPS "0x0: normal operation 0x1: reprogramming 0x2: reserved 0x3: Error Indicator";
CM_ SG_ 234 MDPS_StrTqSnsrVal "Steering torque sensor value Physical Value > 0: Left Direction (CCW) Physical Value < 0: Right Direction (CW) this signal has direction information. '+' Value means Counter clock wise rotation. '-' value means Clock wise rotation.";
CM_ SG_ 234 MDPS_PaStrAnglVal "MDPS_PaSteeringAngleValue ##2G##MDPS - MDPS11 - CR_Mdps_StrAng";
CM_ SG_ 234 MDPS_LoamModSta "MDPS_LoamModeStatus ##2G##MDPS - MDPS11 - CF_Mdps_Loam_Flag";
CM_ SG_ 234 MDPS_HDPSpprtSWVer "HDP-MDPS Control Requirement Spec Version";
CM_ SG_ 234 MDPS_ADASAciActvSta "States for angle control";
CM_ SG_ 234 MDPS_ADASAciPluginSta "ADASAci(HDP) function Plug-in state";
CM_ SG_ 234 MDPS_ADAS_AciFltSig "MDPS fault Status for HDP";
CM_ SG_ 234 MDPS_EstStrAnglVal "This value is used to inform of a compensated steering wheel angle by MDPS . The signal is signed 16bits, and made by motor position sensor. (PH) = (HEX) * 0.1 (for 0 < HEX <= 32767) or = (HEX - 65536) * 0.1 (for HEX > 32767) [Deg] this signal";
CM_ SG_ 234 MDPS_ADASAciActvSta_Lv2 "States for angle control (LV2)";
CM_ SG_ 234 MDPS_ADAS_AciFltSig_Lv2 "MDPS Fault Status for LV2 Angle Control Function";
CM_ SG_ 234 MDPS_TpaPlugInSta "MDPS_TpaPlugInStatus ##2G##MDPS - MDPS11 - CF_Mdps_TPA_FUNC";
CM_ SG_ 234 MDPS_TpaCanfltSta "MDPS_TpaCanFaultStatus ##2G##MDPS - MDPS11 - CF_MDPS_TPACanfailflag";
CM_ SG_ 234 MDPS_TpaModeSta "MDPS_TpaModeStatus ##2G##MDPS - MDPS11 - CF_Mdps_Stat";
CM_ SG_ 234 MDPS_TpaStrAnglVal "MDPS_TpaSteeringAngleValue ##2G##MDPS - MDPS11 - CR_Mdps_StrAng";
CM_ BO_ 272 "Alternative LKAS message, used on cars such as 2023 Ioniq 6, 2nd gen Kona. Matches LKAS except size is 32 bytes";
CM_ SG_ 272 LKA_AVAILABLE "Angle control cars: 3 when LKA is generally available, goes to 0 during changes with LFA";
CM_ SG_ 272 LKAS_ANGLE_CMD "tracks MDPS->STEERING_ANGLE when not engaged, not STEERING_SENSORS->STEERING_ANGLE";
CM_ BO_ 298 "[P] Periodic";
CM_ SG_ 298 ADAS_CMD_Crc30Val "ADAS_CMD_CyclicRedundancyCheck30Value";
CM_ SG_ 298 ADAS_CMD_AlvCnt30Val "ADAS_CMD_AliveCounter30Value";
CM_ SG_ 298 ADAS_StrTqReqVal "LKA_SteeringTorqueRequestValue ##2G##LDW_LKA - LKA11 - CR_LKA_StrToqReq";
CM_ SG_ 298 ADAS_ActToiSta "ADAS_ActiveTorqueOverlayInterfaceStatus ##2G##LDW_LKA - LKA11 - CF_LKA_ActToi";
CM_ SG_ 298 ADAS_ToiFltSta "ADAS_TorqueOverlayInterfaceFaultStatus ##2G##LDW_LKA - LKA11 - CF_LKA_ToiFlt";
CM_ SG_ 298 ADAS_Damping_Gain "ADAS_Damping_Gain";
CM_ SG_ 352 SET_ME_9 "has something to do with AEB settings";
CM_ SG_ 373 ACCEnable "Likely a copy of CAN's TCS13->ACCEnable";
CM_ SG_ 373 DriverBraking "Likely derived from BRAKE->BRAKE_POSITION";
CM_ SG_ 373 DriverBrakingLowSens "Higher threshold version of DriverBraking";
CM_ SG_ 373 PROBABLY_EQUIP "aeb equip?";
CM_ BO_ 384 "[P] Periodic";
CM_ SG_ 384 FR_CMR_Obj_Crc01Val "FR_CMR_Obj_CyclicRedundancyCheck01Value";
CM_ SG_ 384 FR_CMR_Obj_AlvCnt01Val "FR_CMR_Obj_AliveCounter01Value";
CM_ SG_ 384 FR_CMR_Obj_QualLvl01Sta "FR_CMR_Obj_QualityLevel01Value";
CM_ SG_ 384 FR_CMR_Obj_AlvAge01Val "FR_CMR_Obj_AliveAge01Value";
CM_ SG_ 384 FR_CMR_Obj_MvngFlag01Sta "FR_CMR_Obj_MovingFlag01Status";
CM_ SG_ 384 FR_CMR_Obj_Id01Val "FR_CMR_Obj_ID01Value";
CM_ SG_ 384 FR_CMR_Obj_Wth01Val "FR_CMR_Obj_Width01Value";
CM_ SG_ 384 FR_CMR_Obj_Clfct01Sta "FR_CMR_Obj_Classification01Status";
CM_ SG_ 384 FR_CMR_Obj_RelPosX01Val "FR_CMR_Obj_RelativePositionX01Value";
CM_ SG_ 384 FR_CMR_Obj_RelPosY01Val "FR_CMR_Obj_RelativePositionY01Value";
CM_ SG_ 384 FR_CMR_Obj_RelVelX01Val "FR_CMR_Obj_RelativeVelocityX01Value";
CM_ SG_ 384 FR_CMR_Obj_RelVelY01Val "FR_CMR_Obj_RelativeVelocityY01Value";
CM_ SG_ 384 FR_CMR_Obj_RelAccelX01Val "FR_CMR_Obj_RelativeAccelerationX01Value";
CM_ SG_ 384 FR_CMR_Obj_QualLvl02Sta "FR_CMR_Obj_QualityLevel02Value";
CM_ SG_ 384 FR_CMR_Obj_AlvAge02Val "FR_CMR_Obj_AliveAge02Value";
CM_ SG_ 384 FR_CMR_Obj_MvngFlag02Sta "FR_CMR_Obj_MovingFlag02Status";
CM_ SG_ 384 FR_CMR_Obj_Id02Val "FR_CMR_Obj_ID02Value";
CM_ SG_ 384 FR_CMR_Obj_Wth02Val "FR_CMR_Obj_Width02Value";
CM_ SG_ 384 FR_CMR_Obj_Clfct02Sta "FR_CMR_Obj_Classification02Status";
CM_ SG_ 384 FR_CMR_Obj_RelPosX02Val "FR_CMR_Obj_RelativePositionX02Value";
CM_ SG_ 384 FR_CMR_Obj_RelPosY02Val "FR_CMR_Obj_RelativePositionY02Value";
CM_ SG_ 384 FR_CMR_Obj_RelVelX02Val "FR_CMR_Obj_RelativeVelocityX02Value";
CM_ SG_ 384 FR_CMR_Obj_RelVelY02Val "FR_CMR_Obj_RelativeVelocityY02Value";
CM_ SG_ 384 FR_CMR_Obj_RelAccelX02Val "FR_CMR_Obj_RelativeAccelerationX02Value";
CM_ BO_ 385 "[P] Periodic";
CM_ SG_ 385 FR_CMR_Obj_Crc02Val "FR_CMR_Obj_CyclicRedundancyCheck02Value";
CM_ SG_ 385 FR_CMR_Obj_AlvCnt02Val "FR_CMR_Obj_AliveCounter02Value";
CM_ SG_ 385 FR_CMR_Obj_QualLvl03Sta "FR_CMR_Obj_QualityLevel03Value";
CM_ SG_ 385 FR_CMR_Obj_AlvAge03Val "FR_CMR_Obj_AliveAge03Value";
CM_ SG_ 385 FR_CMR_Obj_MvngFlag03Sta "FR_CMR_Obj_MovingFlag03Status";
CM_ SG_ 385 FR_CMR_Obj_Id03Val "FR_CMR_Obj_ID03Value";
CM_ SG_ 385 FR_CMR_Obj_Wth03Val "FR_CMR_Obj_Width03Value";
CM_ SG_ 385 FR_CMR_Obj_Clfct03Sta "FR_CMR_Obj_Classification03Status";
CM_ SG_ 385 FR_CMR_Obj_RelPosX03Val "FR_CMR_Obj_RelativePositionX03Value";
CM_ SG_ 385 FR_CMR_Obj_RelPosY03Val "FR_CMR_Obj_RelativePositionY03Value";
CM_ SG_ 385 FR_CMR_Obj_RelVelX03Val "FR_CMR_Obj_RelativeVelocityX03Value";
CM_ SG_ 385 FR_CMR_Obj_RelVelY03Val "FR_CMR_Obj_RelativeVelocityY03Value";
CM_ SG_ 385 FR_CMR_Obj_RelAccelX03Val "FR_CMR_Obj_RelativeAccelerationX03Value";
CM_ SG_ 385 FR_CMR_Obj_QualLvl04Sta "FR_CMR_Obj_QualityLevel04Value";
CM_ SG_ 385 FR_CMR_Obj_AlvAge04Val "FR_CMR_Obj_AliveAge04Value";
CM_ SG_ 385 FR_CMR_Obj_MvngFlag04Sta "FR_CMR_Obj_MovingFlag04Status";
CM_ SG_ 385 FR_CMR_Obj_Id04Val "FR_CMR_Obj_ID04Value";
CM_ SG_ 385 FR_CMR_Obj_Wth04Val "FR_CMR_Obj_Width04Value";
CM_ SG_ 385 FR_CMR_Obj_Clfct04Sta "FR_CMR_Obj_Classification04Status";
CM_ SG_ 385 FR_CMR_Obj_RelPosX04Val "FR_CMR_Obj_RelativePositionX04Value";
CM_ SG_ 385 FR_CMR_Obj_RelPosY04Val "FR_CMR_Obj_RelativePositionY04Value";
CM_ SG_ 385 FR_CMR_Obj_RelVelX04Val "FR_CMR_Obj_RelativeVelocityX04Value";
CM_ SG_ 385 FR_CMR_Obj_RelVelY04Val "FR_CMR_Obj_RelativeVelocityY04Value";
CM_ SG_ 385 FR_CMR_Obj_RelAccelX04Val "FR_CMR_Obj_RelativeAccelerationX04Value";
CM_ BO_ 386 "[P] Periodic";
CM_ SG_ 386 FR_CMR_Obj_Crc03Val "FR_CMR_Obj_CyclicRedundancyCheck03Value";
CM_ SG_ 386 FR_CMR_Obj_AlvCnt03Val "FR_CMR_Obj_AliveCounter03Value";
CM_ SG_ 386 FR_CMR_Obj_QualLvl05Sta "FR_CMR_Obj_QualityLevel05Value";
CM_ SG_ 386 FR_CMR_Obj_AlvAge05Val "FR_CMR_Obj_AliveAge05Value";
CM_ SG_ 386 FR_CMR_Obj_MvngFlag05Sta "FR_CMR_Obj_MovingFlag05Status";
CM_ SG_ 386 FR_CMR_Obj_Id05Val "FR_CMR_Obj_ID05Value";
CM_ SG_ 386 FR_CMR_Obj_Wth05Val "FR_CMR_Obj_Width05Value";
CM_ SG_ 386 FR_CMR_Obj_Clfct05Sta "FR_CMR_Obj_Classification05Status";
CM_ SG_ 386 FR_CMR_Obj_RelPosX05Val "FR_CMR_Obj_RelativePositionX05Value";
CM_ SG_ 386 FR_CMR_Obj_RelPosY05Val "FR_CMR_Obj_RelativePositionY05Value";
CM_ SG_ 386 FR_CMR_Obj_RelVelX05Val "FR_CMR_Obj_RelativeVelocityX05Value";
CM_ SG_ 386 FR_CMR_Obj_RelVelY05Val "FR_CMR_Obj_RelativeVelocityY05Value";
CM_ SG_ 386 FR_CMR_Obj_RelAccelX05Val "FR_CMR_Obj_RelativeAccelerationX05Value";
CM_ SG_ 386 FR_CMR_Obj_QualLvl06Sta "FR_CMR_Obj_QualityLevel06Value";
CM_ SG_ 386 FR_CMR_Obj_AlvAge06Val "FR_CMR_Obj_AliveAge06Value";
CM_ SG_ 386 FR_CMR_Obj_MvngFlag06Sta "FR_CMR_Obj_MovingFlag06Status";
CM_ SG_ 386 FR_CMR_Obj_Id06Val "FR_CMR_Obj_ID06Value";
CM_ SG_ 386 FR_CMR_Obj_Wth06Val "FR_CMR_Obj_Width06Value";
CM_ SG_ 386 FR_CMR_Obj_Clfct06Sta "FR_CMR_Obj_Classification06Status";
CM_ SG_ 386 FR_CMR_Obj_RelPosX06Val "FR_CMR_Obj_RelativePositionX06Value";
CM_ SG_ 386 FR_CMR_Obj_RelPosY06Val "FR_CMR_Obj_RelativePositionY06Value";
CM_ SG_ 386 FR_CMR_Obj_RelVelX06Val "FR_CMR_Obj_RelativeVelocityX06Value";
CM_ SG_ 386 FR_CMR_Obj_RelVelY06Val "FR_CMR_Obj_RelativeVelocityY06Value";
CM_ SG_ 386 FR_CMR_Obj_RelAccelX06Val "FR_CMR_Obj_RelativeAccelerationX06Value";
CM_ BO_ 387 "[P] Periodic";
CM_ SG_ 387 FR_CMR_Obj_Crc04Val "FR_CMR_Obj_CyclicRedundancyCheck04Value";
CM_ SG_ 387 FR_CMR_Obj_AlvCnt04Val "FR_CMR_Obj_AliveCounter04Value";
CM_ SG_ 387 FR_CMR_Obj_QualLvl07Sta "FR_CMR_Obj_QualityLevel07Value";
CM_ SG_ 387 FR_CMR_Obj_AlvAge07Val "FR_CMR_Obj_AliveAge07Value";
CM_ SG_ 387 FR_CMR_Obj_MvngFlag07Sta "FR_CMR_Obj_MovingFlag07Status";
CM_ SG_ 387 FR_CMR_Obj_Id07Val "FR_CMR_Obj_ID07Value";
CM_ SG_ 387 FR_CMR_Obj_Wth07Val "FR_CMR_Obj_Width07Value";
CM_ SG_ 387 FR_CMR_Obj_Clfct07Sta "FR_CMR_Obj_Classification07Status";
CM_ SG_ 387 FR_CMR_Obj_RelPosX07Val "FR_CMR_Obj_RelativePositionX07Value";
CM_ SG_ 387 FR_CMR_Obj_RelPosY07Val "FR_CMR_Obj_RelativePositionY07Value";
CM_ SG_ 387 FR_CMR_Obj_RelVelX07Val "FR_CMR_Obj_RelativeVelocityX07Value";
CM_ SG_ 387 FR_CMR_Obj_RelVelY07Val "FR_CMR_Obj_RelativeVelocityY07Value";
CM_ SG_ 387 FR_CMR_Obj_RelAccelX07Val "FR_CMR_Obj_RelativeAccelerationX07Value";
CM_ SG_ 387 FR_CMR_Obj_QualLvl08Sta "FR_CMR_Obj_QualityLevel08Value";
CM_ SG_ 387 FR_CMR_Obj_AlvAge08Val "FR_CMR_Obj_AliveAge08Value";
CM_ SG_ 387 FR_CMR_Obj_MvngFlag08Sta "FR_CMR_Obj_MovingFlag08Status";
CM_ SG_ 387 FR_CMR_Obj_Id08Val "FR_CMR_Obj_ID08Value";
CM_ SG_ 387 FR_CMR_Obj_Wth08Val "FR_CMR_Obj_Width08Value";
CM_ SG_ 387 FR_CMR_Obj_Clfct08Sta "FR_CMR_Obj_Classification08Status";
CM_ SG_ 387 FR_CMR_Obj_RelPosX08Val "FR_CMR_Obj_RelativePositionX08Value";
CM_ SG_ 387 FR_CMR_Obj_RelPosY08Val "FR_CMR_Obj_RelativePositionY08Value";
CM_ SG_ 387 FR_CMR_Obj_RelVelX08Val "FR_CMR_Obj_RelativeVelocityX08Value";
CM_ SG_ 387 FR_CMR_Obj_RelVelY08Val "FR_CMR_Obj_RelativeVelocityY08Value";
CM_ SG_ 387 FR_CMR_Obj_RelAccelX08Val "FR_CMR_Obj_RelativeAccelerationX08Value";
CM_ BO_ 388 "[P] Periodic";
CM_ SG_ 388 FR_CMR_Obj_Crc05Val "FR_CMR_Obj_CyclicRedundancyCheck05Value";
CM_ SG_ 388 FR_CMR_Obj_AlvCnt05Val "FR_CMR_Obj_AliveCounter05Value";
CM_ SG_ 388 FR_CMR_Obj_QualLvl09Sta "FR_CMR_Obj_QualityLevel09Value";
CM_ SG_ 388 FR_CMR_Obj_AlvAge09Val "FR_CMR_Obj_AliveAge09Value";
CM_ SG_ 388 FR_CMR_Obj_MvngFlag09Sta "FR_CMR_Obj_MovingFlag09Status";
CM_ SG_ 388 FR_CMR_Obj_Id09Val "FR_CMR_Obj_ID09Value";
CM_ SG_ 388 FR_CMR_Obj_Wth09Val "FR_CMR_Obj_Width09Value";
CM_ SG_ 388 FR_CMR_Obj_Clfct09Sta "FR_CMR_Obj_Classification09Status";
CM_ SG_ 388 FR_CMR_Obj_RelPosX09Val "FR_CMR_Obj_RelativePositionX09Value";
CM_ SG_ 388 FR_CMR_Obj_RelPosY09Val "FR_CMR_Obj_RelativePositionY09Value";
CM_ SG_ 388 FR_CMR_Obj_RelVelX09Val "FR_CMR_Obj_RelativeVelocityX09Value";
CM_ SG_ 388 FR_CMR_Obj_RelVelY09Val "FR_CMR_Obj_RelativeVelocityY09Value";
CM_ SG_ 388 FR_CMR_Obj_RelAccelX09Val "FR_CMR_Obj_RelativeAccelerationX09Value";
CM_ SG_ 388 FR_CMR_Obj_QualLvl10Sta "FR_CMR_Obj_QualityLevel10Value";
CM_ SG_ 388 FR_CMR_Obj_AlvAge10Val "FR_CMR_Obj_AliveAge10Value";
CM_ SG_ 388 FR_CMR_Obj_MvngFlag10Sta "FR_CMR_Obj_MovingFlag10Status";
CM_ SG_ 388 FR_CMR_Obj_Id10Val "FR_CMR_Obj_ID10Value";
CM_ SG_ 388 FR_CMR_Obj_Wth10Val "FR_CMR_Obj_Width10Value";
CM_ SG_ 388 FR_CMR_Obj_Clfct10Sta "FR_CMR_Obj_Classification10Status";
CM_ SG_ 388 FR_CMR_Obj_RelPosX10Val "FR_CMR_Obj_RelativePositionX10Value";
CM_ SG_ 388 FR_CMR_Obj_RelPosY10Val "FR_CMR_Obj_RelativePositionY10Value";
CM_ SG_ 388 FR_CMR_Obj_RelVelX10Val "FR_CMR_Obj_RelativeVelocityX10Value";
CM_ SG_ 388 FR_CMR_Obj_RelVelY10Val "FR_CMR_Obj_RelativeVelocityY10Value";
CM_ SG_ 388 FR_CMR_Obj_RelAccelX10Val "FR_CMR_Obj_RelativeAccelerationX10Value";
CM_ BO_ 389 "[P] Periodic";
CM_ SG_ 389 FR_CMR_Genrl_Crc01Val "FR_CMR_Genrl_CyclicRedundancyCheck01Value";
CM_ SG_ 389 FR_CMR_Genrl_AlvCnt01Val "FR_CMR_Genrl_AliveCounter01Value";
CM_ SG_ 389 FR_CMR_Genrl_DetObjNumVal "FR_CMR_Genrl_DetectionObjectNumberValue";
CM_ SG_ 389 FR_CMR_Genrl_DetLnNumVal "FR_CMR_Genrl_DetectionLineNumberValue";
CM_ SG_ 389 FR_CMR_Genrl_FlInfoSta "FR_CMR_Genrl_FailInformationStatus";
CM_ SG_ 389 FR_CMR_Genrl_SnsrLatencyVal "FR_CMR_Genrl_SensorLatencyValue";
CM_ SG_ 389 FR_CMR_Genrl_DayTimeIndicatorSta "FR_CMR_Genrl_DayTimeIndicatorStatus";
CM_ SG_ 416 VSetDis "set speed in display units";
CM_ BO_ 437 "[P] Periodic";
CM_ SG_ 437 FR_CMR_Crc3Val "FR_CMR_CyclicRedundancyCheck3Value";
CM_ SG_ 437 FR_CMR_AlvCnt3Val "FR_CMR_AliveCounter3Value";
CM_ SG_ 437 Info_LftLnQualSta "Info_LeftLineQualityStatus ##2G##LDW_LKA - LKA14 - CF_LeftLine_Quality";
CM_ SG_ 437 Info_LftLnDptSta "Info_LeftLineDepartureStatus ##2G##LDW_LKA - LKA14 - CF_LeftLine_Departure";
CM_ SG_ 437 Info_LftLnPosVal "Info_LeftLinePositionValue ##2G##LDW_LKA - LKA14 - CF_LeftLine_Position";
CM_ SG_ 437 Info_LftLnHdingAnglVal "Info_LeftLineHeadingAngleValue ##2G##LDW_LKA - LKA14 - CF_LeftLine_HeadingAngle";
CM_ SG_ 437 Info_LftLnCvtrVal "Info_LeftLineCurvatureValue";
CM_ SG_ 437 Info_LftLnCrvtrDrvtvVal "Info_LeftLineCurvatureDerivativeValue";
CM_ SG_ 437 Info_RtLnQualSta "Info_RightLineQualityStatus ##2G##LDW_LKA - LKA14 - CF_RightLine_Quality";
CM_ SG_ 437 Info_RtLnDptSta "Info_RightLineDepartureStatus ##2G##LDW_LKA - LKA14 - CF_RightLine_Departure";
CM_ SG_ 437 Info_RtLnPosVal "Info_RightLinePositionValue ##2G##LDW_LKA - LKA14 - CF_RightLine_Position";
CM_ SG_ 437 Info_RtLnHdingAnglVal "Info_RightLineHeadingAngleValue ##2G##LDW_LKA - LKA14 - CF_RightLine_HeadingAngle";
CM_ SG_ 437 Info_RtLnCvtrVal "Info_RightLineCurvatureValue";
CM_ SG_ 437 Info_RtLnCrvtrDrvtvVal "Info_RightLineCurvatureDerivativeValue";
CM_ SG_ 437 ID_CIPV "ID_CIPV (Valid Object = 1 to 127)";
CM_ SG_ 437 Relative_Velocity "+ : Preceding, - : Oncoming";
CM_ SG_ 437 Longitudinal_Distance "Distance to the object for ISG.";
CM_ SG_ 480 NEW_SIGNAL_5 "todo: figure out why always set to 1";
CM_ SG_ 736 MAX_SPEED "Display units. Restricts car from driving above this speed unless accelerator pedal is depressed beyond pressure point";
CM_ BO_ 866 "Contains signals with detailed lane line information. Used by ADAS ECU on HDA 2 vehicles to operate LFA. Used on cars that use message 272.";
CM_ SG_ 866 LEFT_LANE_LINE "Left lane line confidence";
CM_ SG_ 866 RIGHT_LANE_LINE "Right lane line confidence";
CM_ SG_ 961 COUNTER_ALT "only increments on change";
CM_ SG_ 1041 COUNTER_ALT "only increments on change";
CM_ BO_ 1043 "Lamp signals do not seem universal on cars that use LKAS_ALT, but stalk signals do.";
CM_ SG_ 1043 COUNTER_ALT "only increments on change";
CM_ SG_ 1043 USE_ALT_LAMP "likely 1 on cars that use alt lamp signals";
VAL_ 53 GEAR 0 "P" 5 "D" 6 "N" 7 "R";
VAL_ 64 GEAR 0 "P" 5 "D" 6 "N" 7 "R";
VAL_ 69 GEAR 0 "P" 5 "D" 6 "N" 7 "R";
VAL_ 96 TRACTION_AND_STABILITY_CONTROL 0 "On" 5 "Limited" 1 "Off";
VAL_ 112 GEAR 0 "P" 5 "D" 6 "N" 7 "R";
VAL_ 160 WHL_Crc1Val 0 "0x0x0~0xFFFF:CRCValue" 65535 "0x0x0~0xFFFF:CRCValue";
VAL_ 160 WHL_AlvCnt1Val 0 "0x0x0~0xFF:AlvCntValue" 255 "0x0x0~0xFF:AlvCntValue";
VAL_ 160 WHL_PlsFLVal 255 "Error";
VAL_ 160 WHL_PlsRLVal 255 "Error" 255 "Error";
VAL_ 160 WHL_PlsRRVal 255 "Error";
VAL_ 160 WHL_DirFLVal 0 "Stopped" 1 "Forward" 2 "Reverse";
VAL_ 160 WHL_DirFRVal 0 "Stopped" 1 "Forward" 2 "Reverse";
VAL_ 160 WHL_SpdFLVal 16383 "Error";
VAL_ 160 WHL_SpdFRVal 16383 "Error";
VAL_ 160 WHL_SpdRLVal 16383 "Error";
VAL_ 160 WHL_SpdRRVal 16383 "Error";
VAL_ 203 ADAS_CMD_Crc35Val 0 "0x0x0~0xFFFF:CRCValue" 65535 "0x0x0~0xFFFF:CRCValue";
VAL_ 203 ADAS_CMD_AlvCnt35Val 0 "0x0x0~0xFF:AlvCntValue" 255 "0x0x0~0xFF:AlvCntValue";
VAL_ 203 ADAS_ActvACISta 0 "INIT" 1 "INACTIVE" 2 "ACTIVE35(ACTIVE)" 3 "ACTIVE33(Redundancy)" 4 "RESERVED" 5 "RESERVED" 6 "RESERVED" 7 "RESERVED" 8 "RESERVED" 9 "RESERVED" 10 "RESERVED" 11 "RESERVED" 12 "RESERVED" 13 "RESERVED" 14 "RESERVED" 15 "RESERVED";
VAL_ 203 ADAS_ActvACILvl2Sta 0 "INIT" 1 "INACTIVE" 2 "ACTIVE35(ACTIVE)" 3 "RESERVED" 4 "RESERVED" 5 "RESERVED" 6 "RESERVED" 7 "RESERVED" 8 "RESERVED" 9 "RESERVED" 10 "RESERVED" 11 "RESERVED" 12 "RESERVED" 13 "RESERVED" 14 "RESERVED" 15 "RESERVED" 0 "INIT" 1 "INACTIVE" 2 "ACTIVE35(ACTIVE)" 3 "RESERVED" 4 "RESERVED" 5 "RESERVED" 6 "RESERVED" 7 "RESERVED" 8 "RESERVED" 9 "RESERVED" 10 "RESERVED" 11 "RESERVED" 12 "RESERVED" 13 "RESERVED" 14 "RESERVED" 15 "RESERVED";
VAL_ 203 ADAS_StrAnglReqVal 0 "0x0x000~0x3FFF:Real Values" 16383 "0x0x000~0x3FFF:Real Values";
VAL_ 203 ADAS_ACIAnglTqRedcGainVal 0 "0x0x00~0xFA:Real Values" 250 "0x0x00~0xFA:Real Values" 251 "RESERVED" 252 "RESERVED" 253 "RESERVED" 254 "RESERVED" 255 "RESERVED";
VAL_ 203 FCA_ESA_ActvSta 0 "Inactive" 1 "Active" 2 "RESERVED" 3 "RESERVED";
VAL_ 203 FCA_ESA_TqBstGainVal 0 "0x0x00~0xFA:Real Values" 250 "0x0x00~0xFA:Real Values" 251 "RESERVED" 252 "RESERVED" 253 "RESERVED" 254 "RESERVED" 255 "RESERVED";
VAL_ 234 MDPS_WrngLmpSta 0 "MDPS Malfunction Warning lamp OFF" 1 "MDPS Malfunciton Warning lamp BLANKING(2Hz)" 2 "MDPS Malfunction Warning lamp ON" 3 "MDPS Malfunction Warning lamp BLANKING(1Hz)" 4 "RESERVED" 5 "RESERVED" 6 "RESERVED" 7 "Error Indicator";
VAL_ 234 MDPS_Typ 0 "C-MDPS" 1 "R-MDPS(Dual Pinion)" 2 "R-MDPS(Belt)" 3 "SbW" 4 "RESERVED" 5 "RESERVED" 6 "RESERVED" 7 "Error Indicator";
VAL_ 234 MDPS_EngIdleRpmReq 0 "Current Consumption is Low" 1 "Current Consumption is High" 2 ":RESERVED" 3 "Error Indicator";
VAL_ 234 MDPS_VsmPlgInSta 0 "The VSM function of MDPS is not plugged in (unplugged)." 1 "The VSM function of MDPS is plugged in." 2 "RESERVED" 3 "Error Indicator";
VAL_ 234 MDPS_VsmDfctvSta 0 "MDPS is not defective" 1 "MDPS is defective" 2 "RESERVED" 3 "Error Indicator";
VAL_ 234 MDPS_VsmSigErrSta 0 "VSM1 signal is not error" 1 "VSM signal is error" 2 "RESERVED" 3 "Error Indicator";
VAL_ 234 MDPS_PaPlugInSta 0 "The PA function of MDPS is not plugged in (unplugged)." 1 "The PA function of MDPS is plugged in." 2 "RESERVED" 3 "Error Indicator";
VAL_ 234 MDPS_PaModeSta 0 "RESERVED" 1 "Steering still in initialization phase" 2 "Steering ready, waits for PA command" 3 "Steering set in standby by PA" 4 "Steering requested to go to first activation step" 5 "Steering requested to go to final activation step" 6 "Steering went to error internally" 7 "Steering aborted the automatic function" 8 "RESERVED" 9 "RESERVED" 10 "RESERVED" 11 "RESERVED" 12 "RESERVED" 13 "RESERVED" 14 "RESERVED" 15 "Error Indicator" 0 "RESERVED" 1 "Steering still in initialization phase" 2 "Steering ready, waits for PA command" 3 "Steering set in standby by PA" 4 "Steering requested to go to first activation step" 5 "Steering requested to go to final activation step" 6 "Steering went to error internally" 7 "Steering aborted the automatic function" 8 "RESERVED" 9 "RESERVED" 10 "RESERVED" 11 "RESERVED" 12 "RESERVED" 13 "RESERVED" 14 "RESERVED" 15 "Error Indicator";
VAL_ 234 MDPS_PaCanfltSta 0 "No Failure" 1 "Failure about Pa can message" 2 "RESERVED" 3 "Error Indicator";
VAL_ 234 MDPS_LkaPlgInSta 0 "The LKA function of MDPS is not plugged in (unplugged)." 1 "The LKA function of MDPS is plugged in." 2 "RESERVED" 3 "Error Indicator";
VAL_ 234 MDPS_LkaToiActvSta 0 "Deactivated" 1 "Activated" 2 "RESERVED" 3 "Error Indicator";
VAL_ 234 MDPS_LkaToiUnblSta 0 "Available" 1 "Unavailable" 2 "RESERVED" 3 "Error Indicator";
VAL_ 234 MDPS_LkaToiFltSta 0 "No fault" 1 "Faulty" 2 "RESERVED" 3 "Error Indicator";
VAL_ 234 MDPS_LkaFailSta 0 "Not in fail state" 1 "In fail state" 2 "RESERVED" 3 "Error Indicator";
VAL_ 234 MDPS_ResetOpSta 0 "Normal" 1 "Reset Complete" 2 "Reset Fail" 3 "RESERVED";
VAL_ 234 MDPS_CurrModVal 0 "Comfort Mode" 1 "Sport Mode" 2 "Sport+ Mode" 3 "Chauffeur Mode" 4 "Mild Mode" 5 "Drift Mode" 6 "RESERVED" 7 "Error Indicator";
VAL_ 234 MDPS_OutTqVal 0 "0x0x000~0xFFD:real values" 4093 "0x0x000~0xFFD:real values" 4094 "RESERVED" 4095 "Error Indicator";
VAL_ 234 MDPS_VsmActResp 0 "VSM Control inactivated" 1 "VSM Control Activated" 2 "RESERVED" 3 "Invalid";
VAL_ 234 Reprogram_State_MDPS 0 "normal operation" 1 "reprogramming" 2 "RESERVED" 3 "Error Indicator";
VAL_ 234 MDPS_StrTqSnsrVal 0 "0x0x000~0x1FFD:real values" 8189 "0x0x000~0x1FFD:real values" 8190 "RESERVED" 8191 "Error Indicator";
VAL_ 234 MDPS_PaStrAnglVal 0 "0x0x000~0x7FFD:real values" 32765 "0x0x000~0x7FFD:real values" 32766 "Not Initialized" 32767 "Error Indicator" 32768 "0x8000~0xFFFF:real values" 65535 "0x8000~0xFFFF:real values";
VAL_ 234 MDPS_LoamModSta 0 "Normal" 1 "Loam Flag Warning Display" 2 "RESERVED" 3 "Error Indicator";
VAL_ 234 MDPS_HDPSpprtSWVer 0 "HDP-MDPS Control Requirement Version" 1 "HDP-MDPS Control Requirement Version" 2 "HDP-MDPS Control Requirement Version" 3 "HDP-MDPS Control Requirement Version" 4 "HDP-MDPS Control Requirement Version" 5 "HDP-MDPS Control Requirement Version" 6 "HDP-MDPS Control Requirement Version" 7 "HDP-MDPS Control Requirement Version" 8 "HDP-MDPS Control Requirement Version" 9 "HDP-MDPS Control Requirement Version" 10 "HDP-MDPS Control Requirement Version" 11 "HDP-MDPS Control Requirement Version" 12 "HDP-MDPS Control Requirement Version" 13 "HDP-MDPS Control Requirement Version" 14 "HDP-MDPS Control Requirement Version" 15 "HDP-MDPS Control Requirement Version" 16 "HDP-MDPS Control Requirement Version" 17 "HDP-MDPS Control Requirement Version" 18 "HDP-MDPS Control Requirement Version" 19 "HDP-MDPS Control Requirement Version" 20 "HDP-MDPS Control Requirement Version" 21 "HDP-MDPS Control Requirement Version" 22 "HDP-MDPS Control Requirement Version" 23 "HDP-MDPS Control Requirement Version" 24 "HDP-MDPS Control Requirement Version" 25 "HDP-MDPS Control Requirement Version" 26 "HDP-MDPS Control Requirement Version" 27 "HDP-MDPS Control Requirement Version" 28 "HDP-MDPS Control Requirement Version" 29 "HDP-MDPS Control Requirement Version" 30 "HDP-MDPS Control Requirement Version" 31 "HDP-MDPS Control Requirement Version";
VAL_ 234 MDPS_ADASAciActvSta 0 "INIT" 1 "INACTIVE" 2 "ACTIVE35(ACTIVE)" 3 "ACTIVE33(Redundancy)" 4 "RESERVED" 5 "RESERVED" 6 "RESERVED" 7 "RESERVED" 8 "RESERVED" 9 "RESERVED" 10 "RESERVED" 11 "RESERVED" 12 "RESERVED" 13 "RESERVED" 14 "RESERVED" 15 "RESERVED";
VAL_ 234 MDPS_ADASAciPluginSta 0 "ADASAciNotPlugged-in" 1 "ADASAciPlugged-in" 2 "RESERVED" 3 "ErrorIndicator";
VAL_ 234 MDPS_ADAS_AciFltSig 0 "No Fault" 1 "MDPS Fault" 2 "Fault Except MDPS" 3 "Both Fault";
VAL_ 234 MDPS_EstStrAnglVal 0 "0x0x000~0x7FFD:real values" 32765 "0x0x000~0x7FFD:real values" 32766 "Not Initialized" 32767 "Error Indicator" 32768 "0x8000~0xFFFF:real values" 65535 "0x8000~0xFFFF:real values";
VAL_ 234 MDPS_ADASAciActvSta_Lv2 0 "Not USED" 1 "INACTIVE" 2 "ACTIVE35(Active)" 3 "Reserved" 4 "Reserved" 5 "Reserved" 6 "Reserved" 7 "Reserved" 8 "Reserved" 9 "Reserved" 10 "Reserved" 11 "Reserved" 12 "Reserved" 13 "Reserved" 14 "Reserved" 15 "Reserved";
VAL_ 234 MDPS_ADAS_AciFltSig_Lv2 0 "No Fault" 1 "MDPS Fault" 2 "Fault Except MDPS" 3 "Both Fault" 4 "Temporarily Unavailable" 5 "Temporarily Unavailable and MDPS Fault" 6 "Temporarily Unavailable and Fault Except MDPS" 7 "Temporarily Unavailable and Both Fault";
VAL_ 234 MDPS_TpaPlugInSta 0 "The TPA function of MDPS is not plugged in (unplugged)" 1 "The TPA function of MDPS is plugged in" 2 "RESERVED" 3 "Error Indicator";
VAL_ 234 MDPS_TpaCanfltSta 0 "No Failure" 1 "Failure about Tpa can message" 2 "RESERVED" 3 "Error Indicator";
VAL_ 234 MDPS_TpaModeSta 0 "RESERVED" 1 "Steering still in initialization phase" 2 "Steering ready, waits for TPA command" 3 "Steering set in standby by TPA" 4 "Steering requested to go to first activation step activation step" 5 "Steering requested to go to final activation step" 6 "Steering went to error internally" 7 "Steering aborted the automatic function" 14 "RESERVED" 15 "Error Indicator";
VAL_ 234 MDPS_TpaStrAnglVal 0 "0x0x000~0x7FFD:real values" 32765 "0x0x000~0x7FFD:real values" 32766 "Not Initialized" 32767 "Error Indicator" 32768 "0x8000~0xFFFF:real values" 65535 "0x8000~0xFFFF:real values";
VAL_ 272 LKA_MODE 1 "warning only" 2 "assist" 6 "off";
VAL_ 272 LKA_ICON 0 "hidden" 1 "grey" 2 "green" 3 "flashing green";
VAL_ 272 LKAS_ANGLE_ACTIVE 0 "off" 1 "not active" 2 "active";
VAL_ 293 SAS_AnglVal 0 "0x0x0000~0x7FFE:real value" 32766 "0x0x0000~0x7FFE:real value" 32767 "Error Indicator" 32768 "0x8000~0xFFFF:real value" 65535 "0x8000~0xFFFF:real value";
VAL_ 293 SAS_SpdVal 0 "0x0x00~0xFE:real value" 254 "0x0x00~0xFE:real value" 255 "Error Indicator";
VAL_ 293 SAS_IntSta 0 "real vaule" 1 "real vaule" 2 "real vaule" 3 "real vaule" 4 "real vaule" 5 "real vaule" 6 "real vaule" 7 "real vaule" 8 "real vaule" 9 "real vaule" 10 "real vaule" 11 "real vaule" 12 "real vaule" 13 "real vaule" 14 "real vaule" 15 "real vaule" 16 "0x10~0xFF:RESERVED" 255 "0x10~0xFF:RESERVED";
VAL_ 298 ADAS_CMD_Crc30Val 0 "0x0x0~0xFFFF:CRCValue" 65535 "0x0x0~0xFFFF:CRCValue";
VAL_ 298 ADAS_CMD_AlvCnt30Val 0 "0x0x0~0xFF:AlvCntValue" 255 "0x0x0~0xFF:AlvCntValue";
VAL_ 298 ADAS_StrTqReqVal 0 "0x0x000~0x7FD:0~2045" 2045 "0x0x000~0x7FD:0~2045" 2046 "Reserved" 2047 "Invalid";
VAL_ 298 ADAS_ActToiSta 0 "De-activate TOI" 1 "Activate TOI" 2 "Reserved" 3 "Error indicator";
VAL_ 298 ADAS_ToiFltSta 0 "No Fault" 1 "Fault" 2 "Reserved" 3 "Error indicatorr";
VAL_ 298 ADAS_Damping_Gain 0 "Reserved" 1 "Reserved" 2 "Reserved" 3 "0x3~0xC8:3 ~ 200%" 200 "0x3~0xC8:3 ~ 200%" 201 "Reserved" 202 "Reserved" 203 "Reserved" 204 "Reserved" 205 "Reserved" 206 "Reserved" 207 "Reserved" 208 "Reserved" 209 "Reserved" 210 "Reserved" 211 "Reserved" 212 "Reserved" 213 "Reserved" 214 "Reserved" 215 "Reserved" 216 "Reserved" 217 "Reserved" 218 "Reserved" 219 "Reserved" 220 "Reserved" 221 "Reserved" 222 "Reserved" 223 "Reserved" 224 "Reserved" 225 "Reserved" 226 "Reserved" 227 "Reserved" 228 "Reserved" 229 "Reserved" 230 "Reserved" 231 "Reserved" 232 "Reserved" 233 "Reserved" 234 "Reserved" 235 "Reserved" 236 "Reserved" 237 "Reserved" 238 "Reserved" 239 "Reserved" 240 "Reserved" 241 "Reserved" 242 "Reserved" 243 "Reserved" 244 "Reserved" 245 "Reserved" 246 "Reserved" 247 "Reserved" 248 "Reserved" 249 "Reserved" 250 "Reserved" 251 "Reserved" 252 "Reserved" 253 "Reserved" 254 "Reserved" 255 "Reserved";
VAL_ 304 PARK_BUTTON 1 "Pressed" 2 "Not Pressed";
VAL_ 304 KNOB_POSITION 1 "R" 2 "N (on R side)" 3 "Centered" 4 "N (on D side)" 5 "D";
VAL_ 304 GEAR 1 "P" 2 "R" 3 "N" 4 "D";
VAL_ 352 AEB_SETTING 1 "off" 2 "warning only" 3 "active assist";
VAL_ 353 FCA_ICON 0 "HIDDEN" 1 "ORANGE" 2 "RED";
VAL_ 353 FCA_ALT_ICON 0 "HIDDEN" 1 "ORANGE" 3 "RED";
VAL_ 353 LKA_ICON 0 "HIDDEN" 1 "ORANGE" 3 "GRAY" 4 "GREEN";
VAL_ 353 HBA_ICON 0 "HIDDEN" 1 "GRAY" 2 "GREEN";
VAL_ 353 FCA_IMAGE 0 "HIDDEN" 2 "VISIBLE";
VAL_ 353 BCA_LEFT 0 "HIDDEN" 1 "VISIBLE" 2 "VISIBLE+ICON";
VAL_ 353 BCA_RIGHT 0 "HIDDEN" 1 "VISIBLE" 2 "VISIBLE+ICON";
VAL_ 353 LCA_LEFT_ARROW 0 "HIDDEN" 1 "VISIBLE";
VAL_ 353 LCA_RIGHT_ARROW 0 "HIDDEN" 1 "VISIBLE";
VAL_ 353 CENTERLINE 0 "HIDDEN" 1 "GREEN";
VAL_ 353 TARGET 0 "HIDDEN" 1 "BLUE" 3 "WHITE";
VAL_ 353 LANELINE_LEFT 0 "GRAY" 1 "HIDDEN" 2 "WHITE" 4 "ORANGE" 6 "GREEN";
VAL_ 353 LANELINE_RIGHT 0 "GRAY" 1 "HIDDEN" 2 "WHITE" 4 "ORANGE" 6 "GREEN";
VAL_ 353 LANE_HIGHLIGHT 0 "HIDDEN" 1 "GREEN" 2 "WHITE" 3 "BLUE" 4 "ORANGE" 5 "RED";
VAL_ 353 LANE_LEFT 0 "HIDDEN" 1 "GREEN";
VAL_ 353 LANE_RIGHT 0 "HIDDEN" 1 "GREEN";
VAL_ 353 LANE_ZOOM 0 "ZOOM" 1 "HIDDEN";
VAL_ 353 ALERTS_1 0 "HIDDEN" 1 "WARNING_ONLY_CAR_CENTER" 2 "WARNING_ONLY_CAR_LEFT" 3 "WARNING_ONLY_CAR_RIGHT" 4 "WARNING_ONLY_LEFT" 5 "WARNING_ONLY_RIGHT" 11 "EMERGENCY_BRAKING_CAR_CENTER" 12 "EMERGENCY_BRAKING_CAR_LEFT" 13 "EMERGENCY_BRAKING_CAR_RIGHT" 14 "EMERGENCY_BRAKING_LEFT" 15 "EMERGENCY_BRAKING_RIGHT" 21 "EMERGENCY_STEERING_CAR_LEFT" 22 "EMERGENCY_STEERING_CAR_RIGHT" 23 "EMERGENCY_STEERING_CAR_LEFT_AWAY" 24 "EMERGENCY_STEERING_CAR_RIGHT_AWAY" 25 "EMERGENCY_STEERING_REAR_LEFT" 26 "EMERGENCY_STEERING_REAR_RIGHT" 33 "DRIVE_CAREFULLY";
VAL_ 353 ALERTS_2 0 "HIDDEN" 1 "KEEP_HANDS_ON_STEERING_WHEEL" 2 "KEEP_HANDS_ON_STEERING_WHEEL_RED" 3 "LANE_FOLLOWING_ASSIST_DEACTIVATED" 4 "HIGHWAY_DRIVING_ASSIST_DEACTIVATED" 5 "CONSIDER_TAKING_A_BREAK" 6 "PRESS_OK_BUTTON_TO_ENABLE_LANE_CHANGE_ASSIST" 7 "COLLISION_RISK_VEHICLE_TAKING_EMERGENCY_CONTROL" 8 "TAKE_CONTROL_OF_THE_VEHICLE_IMMEDIATELY_VEHICLE_IS_STOPPING" 9 "TAKE_CONTROL_OF_THE_VEHICLE_IMMEDIATELY" 11 "HIGHWAY_DRIVING_PILOT_SYSTEM_DEACTIVATED_AUDIBLE" 12 "KEEP_YOUR_EYES_ON_THE_ROAD" 13 "HIGHWAY_DRIVING_PILOT_CONDITIONS_NOT_MET_AUDIBLE" 14 "COLLISION_RISK_VEHICLE_TAKING_EMERGENCY_CONTROL" 15 "SET_THE_WIPER_AND_LIGHT_CONTROLS_TO_AUTO" 16 "BE_PREPARED_TO_TAKE_CONTROL_OF_THE_VEHICLE_AT_ANY_TIME" 21 "TAKE_CONTROL_OF_THE_VEHICLE_IMMEDIATELY_VEHICLE_IS_STOPPING" 10 "TAKE_CONTROL_OF_THE_VEHICLE_IMMEDIATELY";
VAL_ 353 ALERTS_3 1 "AUTOMATICALLY_ADJUSTING_TO_THE_POSTED_SPEED_LIMIT" 2 "SET_SPEED_CHANGED" 3 "AUTOMATICALLY_ADJUSTING_TO_THE_POSTED_SPEED_LIMIT" 4 "SET_SPEED_CHANGED" 7 "DISTANCE_1" 8 "DISTANCE_2" 9 "DISTANCE_3" 10 "DISTANCE_4" 17 "DRIVE_CAREFULLY" 18 "CHECK_SURROUNDINGS" 19 "CONDITIONS_NOT_MET" 20 "LANES_NOT_DETECTED" 21 "CURVE_TOO_SHARP" 22 "LANE_TOO_NARROW" 23 "ROAD_TYPE_NOT_SUPPORTED" 24 "UNAVAILABLE_WITH_HAZARD_LIGHTS_ON" 25 "VEHICLE_SPEED_IS_TOO_LOW" 26 "KEEP_HANDS_ON_STEERING_WHEEL" 27 "LANE_TYPE_NOT_SUPPORTED" 28 "LANE_ASSIST_CANCELED_STEERING_INPUT_DETECTED" 0 "HIDDEN";
VAL_ 353 ALERTS_4 0 "HIDDEN" 1 "TAKE_FOOT_OFF_THE_ACCELERATOR_PEDAL" 2 "TAKE_FOOT_OFF_THE_BRAKE_PEDAL" 3 "UNAVAILABLE_WHILE_HIGHWAY_DRIVING_PILOT_SYSTEM_IS_ACTIVE" 4 "TO_EXIT_HDP_GRASP_THE_STEERING_WHEEL_THEN_PRESS_AND_HOLD_THE_HDP_BUTTON" 5 "ACCELERATOR_PEDAL_OPERATION_LIMITED_FOR_SAFETY" 6 "TURN_OFF_HAZARD_WARNING_LIGHTS_AND_TURN_SIGNAL" 7 "KEEP_THE_DRIVERS_SEAT_IN_A_SAFE_DRIVING_POSITION" 16 "SET_SPEED_CHANGED" 17 "ACTIVATING_WINDSHIELD_DEFOG_TO_MAINTAIN_THE_DRIVERS_VIEW" 18 "SET_THE_WIPER_AND_LIGHT_CONTROLS_TO_AUTO" 19 "VEHICLE_SPEED_REDUCED_FOR_SAFETY_MERGING_LANES_AHEAD" 20 "SPEED_REDUCED_FOR_SAFETY_CONSTRUCTION_ZONE_DETECTED" 21 "VEHICLE_SPEED_LIMITED_SENSOR_DETECTION_RANGE_LIMITED" 22 "PREPARE_TO_TAKE_CONTROL_UNSUPPORTED_ROAD_TYPE_AHEAD" 23 "PREPARE_TO_TAKE_CONTROL_ENTRANCE_AND_EXIT_RAMPS_AHEAD" 24 "PREPARE_TO_TAKE_CONTROL_TOLLGATE_AHEAD" 25 "PREPARE_TO_TAKE_CONTROL_ROAD_EVENT_AHEAD" 26 "CLEARING_PATH_FOR_EMERGENCY_VEHICLE" 27 "VEHICLE_IS_TOO_SLOW_COMPARED_TO_TRAFFIC_FLOW" 28 "AFTER_SUNSET_HDP_IS_AVAILABLE_IN_AN_INSIDE_LANE_BEHIND_A_LEADING_VEHICLE" 29 "VEHICLE_SPEED_LIMITED_MERGING_LANES_AHEAD" 30 "VEHICLE_SPEED_LIMITED_CONSTRUCTION_ZONE_DETECTED" 31 "VEHICLE_SPEED_TEMPORARILY_LIMITED_FOR_SAFETY" 32 "PRESS_AND_HOLD_THE_BUTTON_TO_ACTIVATE_HIGHWAY_DRIVING_PILOT" 40 "HIGHWAY_DRIVING_PILOT_SYSTEM_IS_AVAILABLE" 64 "RESTART_VEHICLE_AFTER_EMERGENCY_STOP" 65 "CONNECTED_SERVICES_UNAVAILABLE" 66 "AVAILABLE_AFTER_VEHICLE_SOFTWARE_IS_UPDATED" 67 "ROAD_TYPE_NOT_SUPPORTED" 68 "ONLY_AVAILABLE_WHILE_DRIVING_ON_HIGHWAY_LANES" 69 "UNAVAILABLE_WHILE_OTHER_WARNINGS_ARE_ACTIVE" 70 "CANNOT_ACTIVATE_AT_ENTRANCE_EXIT_RAMPS" 71 "LANE_UNSUPPORTED" 72 "NOT_AVAILABLE_IN_THIS_COUNTRY" 79 "CHECKING_THE_DETECTION_RANGE_OF_THE_SENSOR" 80 "SHIFT_TO_D" 81 "ENGINE_STOPPED_BY_AUTO_STOP" 82 "INCREASE_DISTANCE_FROM_VEHICLE_AHEAD" 83 "VEHICLE_SPEED_IS_TOO_HIGH" 84 "CENTER_VEHICLE_IN_THE_LANE" 85 "PARKING_ASSIST_IS_ACTIVE" 86 "ESC_ACTIVIATION_REQUIRED" 87 "UNFOLD_SIDE_VIEW_MIRRORS" 88 "UNAVAILABLE_IN_THE_OUTER_LANE_AFTER_SUNSET" 89 "VEHICLE_SPEED_LIMITED_AFTER_SUNSET_FOR_SAFETY" 90 "LEADING_VEHICLE_NOT_DETECTED" 104 "AGGRESSIVE_BRAKING_OR_STEERING_DETECTED" 110 "SENSOR_AUTO_CALIBRATION_IN_PROGRESS_THIS_MAY_TAKE_SEVERAL_MINUTES" 111 "HIGHWAY_DRIVING_PILOT_WILL_BE_AVAILABLE_SHORTLY" 112 "IF_STEERING_WHEEL_IS_USED_HDP_WILL_BE_DEACTIVATED" 120 "IMPACT_DETECTED" 128 "UNSUITABLE_USE_OF_ACCELERATOR_PEDAL_DETECTED" 129 "GEAR_SHIFTER_USE_DETECTED" 130 "UNSUITABLE_BRAKE_PEDAL_USE_DETECTED" 131 "VEHICLE_START_BUTTON_PRESSED" 132 "VEHICLE_HAS_BEEN_STOPPED_FOR_TOO_LONG" 141 "TRAFFIC_CONGESTION_HAS_CLEARED" 142 "ENTRANCE_AND_EXIT_RAMPS_AHEAD" 143 "UNSUPPORTED_LANE_AHEAD" 144 "UNSUPPORTED_ROAD_TYPE_AHEAD" 145 "LANE_DEPARTURE_DETECTED" 146 "MAXIMUM_SPEED_EXCEEDED" 147 "HIGHWAY_DRIVING_PILOT_LIMITED_ABNORMAL_VEHICLE_CONTROLLER_STATUS" 148 "WIPER_LIGHT_CONTROL_SETTINGS_ARE_UNSUITABLE_FOR_USE_WITH_HDP" 149 "WINDSHIELD_DEFOG_SYSTEM_STATUS_IS_UNSUITABLE_FOR_USE_WITH_HDP" 150 "HAZARD_WARNING_LIGHTS_OR_TURN_SIGNAL_OPERATION_DETECTED" 151 "PERFORMING_EVASIVE_STEERING_OBSTACLES_DETECTED_AHEAD" 152 "HIGHWAY_DRIVING_PILOT_LIMITED_SENSOR_DETECTION_RANGE_LIMITED" 160 "CHECK_HIGHWAY_DRIVING_PILOT_SYSTEM" 161 "SAFETY_FUNCTION_ACTIVATED" 176 "CAMERA_OBSCURED" 177 "RADAR_BLOCKED" 178 "LIDAR_BLOCKED" 179 "AIRBAG_WARNING_LIGHT_IS_ON" 180 "ATTACHED_TRAILED_DETECTED" 181 "HIGH_OUTSIDE_TEMPERATURE" 182 "LOW_OUTSIDE_TEMPERATURE" 190 "UNAVAILABLE_DUE_TO_THE_ROAD_EVENT_INFORMATION_RECEIVED" 191 "UNAVAILABLE_NEAR_TOLLGATES" 192 "DRIVERS_SEAT_IS_NOT_IN_A_SAFE_DRIVING_POSITION" 193 "VEHICLE_DRIVING_THE_WRONG_WAY_DETECTED_AHEAD" 194 "EMERGENCY_VEHICLE_DETECTED" 195 "OBSTACLE_DETECTED_AHEAD" 196 "SENSOR_BLOCKED_DUE_TO_RAIN_SNOW_OR_ROAD_DEBRIS" 197 "SLIPPERY_ROAD_SURFACE_DETECTED" 198 "CONSTRUCTION_ZONE_DETECTED_AHEAD" 199 "PEDESTRIAN_DETECTED_AHEAD" 200 "UNSUITABLE_DRIVERS_SEAT_POSITION_DETECTED" 201 "FOLDED_SIDE_VIEW_MIRRORS_DETECTED" 208 "VEHICLE_POSITION_NOT_DETECTED" 209 "LANE_NOT_DETECTED" 210 "DRIVER_NOT_DETECTED" 211 "KEEP_YOUR_EYES_ON_THE_ROAD" 212 "LEADING_VEHICLE_REQUIRED_AFTER_SUNSET" 213 "TBD" 240 "LOW_FUEL" 241 "LOW_TIRE_PRESSURE" 242 "DOOR_OPEN" 243 "TRUNK_OPEN" 244 "HOOD_OPEN" 245 "SEAT_BELT_NOT_FASTENED" 246 "PARKING_BRAKE_ACTIVATED" 247 "LOW_EV_BATTERY" 248 "HDP_DEACTIVATION_DELAYED_RISK_OF_COLLISION_DETECTED" 249 "LIFTGATE_OPENED";
VAL_ 353 ALERTS_5 0 "HIDDEN" 1 "DRIVERS_GRASP_NOT_DETECTED_DRIVING_SPEED_WILL_BE_LIMITED" 2 "WATCH_FOR_SURROUNDING_VEHICLES" 3 "SMART_CRUISE_CONTROL_DEACTIVATED" 4 "SMART_CRUISE_CONTROL_CONDITIONS_NOT_MET" 5 "USE_SWITCH_OR_PEDAL_TO_ACCELERATE" 6 "DRIVER_ASSISTNCE_SYSTEM_LIMITED_TRAILER_ATTACHED" 7 "DRIVER_ASSISTNCE_SYSTEM_LIMITED_DRIVER_FULL_FACE_NOT_VISIBLE" 11 "LEADING_VEHICLE_IS_DRIVING_AWAY" 12 "STOP_VEHICLE_THEN_TRY_AGAIN" 19 "ACTIVATING_HIGHWAY_DRIVING_PILOT_SYSTEM" 20 "CONTINUING_USE_OF_HIGHWAY_DRIVING_PILOT_WILL_RESULT_IN_DEVIATION_FROM_THE_NAVIGATION_ROUTE" 21 "HIGHWAY_DRIVING_PILOT_SYSTEM_DEACTIVATED_SILENT" 22 "HIGHWAY_DRIVING_PILOT_SYSTEM_NOT_APPLIED" 23 "HIGHWAY_DRIVING_PILOT_CONDITIONS_NOT_MET_SILENT";
VAL_ 353 MUTE 0 "NONE" 1 "MUTED";
VAL_ 353 SOUNDS_1 0 "NONE" 3 "FAST BEEP" 6 "CONSTANT BEEP";
VAL_ 353 SOUNDS_2 0 "NONE" 2 "SINGLE CHIME" 3 "CONSTANT CHIME" 6 "FAST BEEP";
VAL_ 353 SOUNDS_3 0 "NONE" 3 "SOFT CHIME" 5 "SINGLE CHIME";
VAL_ 353 SOUNDS_4 0 "NONE" 2 "DOUBLE CHIME";
VAL_ 353 SETSPEED_HUD 0 "HIDDEN" 1 "GRAY" 2 "GREEN" 3 "WHITE" 5 "CYAN";
VAL_ 353 DISTANCE_LEAD 0 "HIDDEN" 1 "GRAY" 2 "WHITE";
VAL_ 353 DISTANCE_CAR 0 "HIDDEN" 1 "GRAY" 2 "WHITE" 3 "CYAN A";
VAL_ 353 DISTANCE_SPACING 0 "HIDDEN" 1 "BLUE" 3 "WHITE" 5 "CYAN";
VAL_ 353 SETSPEED 0 "HIDDEN" 1 "GRAY" 2 "GREEN" 3 "WHITE" 6 "CYAN";
VAL_ 353 HDA_ICON 0 "HIDDEN" 1 "GRAY" 2 "GREEN" 3 "WHITE" 5 "CYAN HDP";
VAL_ 353 SLA_ICON 0 "HIDDEN" 1 "WHITE UP" 2 "WHITE DOWN" 3 "GREEN UP" 4 "GREEN DOWN";
VAL_ 353 NAV_ICON 0 "HIDDEN" 1 "GRAY" 2 "GREEN" 4 "WHITE";
VAL_ 353 LFA_ICON 0 "HIDDEN" 1 "GRAY" 2 "GREEN" 3 "WHITE" 5 "CYAN";
VAL_ 353 LCA_LEFT_ICON 0 "HIDDEN" 1 "GRAY" 2 "GREEN" 4 "WHITE";
VAL_ 353 LCA_RIGHT_ICON 0 "HIDDEN" 1 "GRAY" 2 "GREEN" 4 "WHITE";
VAL_ 353 BACKGROUND 0 "HIDDEN" 1 "BLUE" 3 "ORANGE" 4 "FLASHING ORANGE" 6 "FLASHING RED" 7 "GRAY";
VAL_ 353 DAW_ICON 0 "HIDDEN" 1 "ORANGE";
VAL_ 353 CAR_CIRCLE 0 "HIDDEN" 1 "GRAY" 2 "CYAN";
VAL_ 354 COUNTRY 0 "HIDDEN" 1 "SOUTH_KOREA" 4 "INTL" 5 "JAPAN" 6 "CANADA" 7 "USA" 8 "CHINA" 9 "INTL";
VAL_ 354 SPEEDLIMIT_FLASH 0 "HIDDEN" 1 "ERROR" 2 "NORMAL" 4 "RED";
VAL_ 354 SIGNS 0 "HIDDEN" 1 "PEDESTRIAN_CROSSING" 2 "SCHOOL_CROSSWALK" 8 "STOP" 9 "YIELD" 16 "DO_NOT_PASS" 19 "DO_NOT_ENTER" 24 "ROUNDABOUT" 26 "RIGHT_CURVE_AHEAD" 27 "LEFT_CURVE_AHEAD" 28 "SLIGHT_RIGHT_CURVE_AHEAD" 29 "SLIGHT_LEFT_CURVE_AHEAD";
VAL_ 354 SPEEDLIMIT_WEATHER 0 "HIDDEN" 1 "RAIN" 2 "SNOW" 3 "RAIN+SNOW" 4 "TRAILER";
VAL_ 354 VIBRATE 0 "NONE" 1 "VIBRATE";
VAL_ 354 LEAD 0 "HIDDEN" 1 "GRAY BOX" 2 "WHITE BOX" 3 "GRAY CAR" 4 "WHITE CAR" 5 "GRAY TRUCK" 6 "WHITE TRUCK" 7 "GRAY PERSON" 8 "WHITE PERSON" 9 "GRAY BICYCLE" 10 "WHITE BICYCLE" 11 "GRAY MOTORCYCLE" 12 "WHITE MOTORCYCLE" 13 "DARK CONE" 14 "ORANGE CONE";
VAL_ 354 LEAD_ALT 0 "HIDDEN" 1 "GRAY BOX" 2 "WHITE BOX" 3 "DIM CONE" 4 "ORANGE CONE";
VAL_ 354 LEAD_LEFT 0 "HIDDEN" 1 "GRAY BOX" 2 "WHITE BOX" 3 "GRAY CAR" 4 "WHITE CAR" 5 "GRAY TRUCK" 6 "WHITE TRUCK" 7 "GRAY PERSON" 8 "WHITE PERSON" 9 "GRAY BICYCLE" 10 "WHITE BICYCLE" 11 "GRAY MOTORCYCLE" 12 "WHITE MOTORCYCLE" 13 "DARK CONE" 14 "ORANGE CONE";
VAL_ 354 LEAD_RIGHT 0 "HIDDEN" 1 "GRAY BOX" 2 "WHITE BOX" 3 "GRAY CAR" 4 "WHITE CAR" 5 "GRAY TRUCK" 6 "WHITE TRUCK" 7 "GRAY PERSON" 8 "WHITE PERSON" 9 "GRAY BICYCLE" 10 "WHITE BICYCLE" 11 "GRAY MOTORCYCLE" 12 "WHITE MOTORCYCLE" 13 "DARK CONE" 14 "ORANGE CONE";
VAL_ 354 FAULT_FSS 0 "HIDDEN" 1 "CHECK_FORWARD_SAFETY_SYSTEM" 2 "FORWARD_SAFETY_SYSTEM_LIMITED_CAMERA_OBSCURED" 3 "FORWARD_SAFETY_SYSTEM_LIMITED_RADAR_BLOCKED";
VAL_ 354 FAULT_FCA 0 "HIDDEN" 1 "CHECK_FORWARD_SIDE_SAFETY_SYSTEM" 2 "FORWARD_SIDE_SAFETY_SYSTEM_LIMITED_CAMERA_OBSCURED" 3 "FORWARD_SIDE_SAFETY_SYSTEM_LIMITED_RADAR_BLOCKED";
VAL_ 354 FAULT_LSS 0 "HIDDEN" 1 "CHECK_LANE_SAFETY_SYSTEM" 2 "LANE_SAFETY_SYSTEM_DISABLED_CAMERA_OBSCURED";
VAL_ 354 FAULT_SLA 0 "HIDDEN" 1 "CHECK_SPEED_LIMIT_SYSTEM" 2 "SPEED_LIMIT_SYSTEM_DISABLED_CAMERA_OBSCURED";
VAL_ 354 FAULT_DAW 0 "HIDDEN" 1 "CHECK_INATTENTIVE_DRIVING_WARNING_SYSTEM" 2 "INATTENTIVE_DRIVING_WARNING_SYSTEM_DISABLED_CAMERA_OBSCURED";
VAL_ 354 FAULT_HBA 0 "HIDDEN" 1 "CHECK_HIGH_BEAM_ASSIST_SYSTEM";
VAL_ 354 FAULT_SCC 0 "HIDDEN" 1 "CHECK_SMART_CRUISE_CONTROL_SYSTEM" 2 "SMART_CRUISE_CONTROL_DISABLED_RADAR_BLOCKED";
VAL_ 354 FAULT_LFA 0 "HIDDEN" 1 "CHECK_LANE_FOLLOWING_SYSTEM_ASSIST_SYSTEM";
VAL_ 354 FAULT_HDA 0 "HIDDEN" 1 "CHECK_HIGHWAY_DRIVING_ASSIST_SYSTEM";
VAL_ 354 FAULT_LCA 0 "HIDDEN" 1 "CHECK_LANE_CHANGE_ASSIST_FUNCTION" 2 "LANE_CHANGE_ASSIST_FUNCTION_DISABLED_CAMERA_OBSCURED" 3 "LANE_CHANGE_ASSIST_FUNCTION_DISABLED_RADAR_BLOCKED";
VAL_ 354 FAULT_HDP 0 "HIDDEN" 1 "CHECK_HIGHWAY_DRIVING_PILOT_SYSTEM" 2 "HIGHWAY_DRIVING_PILOT_DISABLED_CAMERA_OBSCURED" 3 "HIGHWAY_DRIVING_PILOT_DISABLED_RADAR_BLOCKED" 4 "HIGHWAY_DRIVING_PILOT_DISABLED_LIDAR_BLOCKED";
VAL_ 354 FAULT_DAS 0 "HIDDEN" 1 "CHECK_DRIVER_ASSISTANCE_SYSTEM" 2 "DRIVER_ASSISTANCE_SYSTEM_LIMITED_CAMERA_OBSCURED" 3 "DRIVER_ASSISTANCE_SYSTEM_LIMITED_RADAR_BLOCKED" 4 "DRIVER_ASSISTANCE_SYSTEM_LIMITED_CAMERA_OBSCURED_AND_RADAR_BLOCKED";
VAL_ 354 FAULT_ESS 0 "HIDDEN" 1 "CHECK_EMERGENCY_STOPPING_FUNCTION" 2 "EMERGENCY_STOPPING_FUNCTION_DISABLED_CAMERA_OBSCURED" 3 "EMERGENCY_STOPPING_FUNCTION_DISABLED_RADAR_BLOCKED";
VAL_ 362 BLINKER_CONTROL 1 "hazards" 2 "hazards button backlight" 3 "left blinkers" 4 "right blinkers";
VAL_ 373 ACCEnable 0 "SCC ready" 1 "SCC temp fault" 2 "SCC permanent fault" 3 "SCC permanent fault, communication issue";
VAL_ 416 ACCMode 0 "off" 1 "enabled" 2 "driver_override" 3 "off_maybe_fault" 4 "cancelled";
VAL_ 426 CRUISE_BUTTONS 0 "none" 1 "res_accel" 2 "set_decel" 3 "gap_distance" 4 "pause_resume";
VAL_ 463 CRUISE_BUTTONS 0 "none" 1 "res_accel" 2 "set_decel" 3 "gap_distance" 4 "pause_resume";
VAL_ 463 RIGHT_PADDLE 0 "Not Pulled" 1 "Pulled";
VAL_ 463 LEFT_PADDLE 0 "Not Pulled" 1 "Pulled";
VAL_ 736 MSLA_STATUS 0 "disabled" 1 "active" 2 "paused";
VAL_ 866 LEFT_LANE_LINE 0 "Not Detected" 1 "Low Confidence" 2 "Medium Confidence" 3 "High Confidence";
VAL_ 866 RIGHT_LANE_LINE 0 "Not Detected" 1 "Low Confidence" 2 "Medium Confidence" 3 "High Confidence";
VAL_ 1041 DRIVER_DOOR 0 "Closed" 1 "Opened";
VAL_ 1041 PASSENGER_DOOR 0 "Closed" 1 "Opened";
VAL_ 1041 PASSENGER_SEATBELT 0 "Unlatched" 1 "Latched";
VAL_ 1041 DRIVER_SEATBELT 0 "Unlatched" 1 "Latched";
VAL_ 1041 DRIVER_REAR_DOOR 0 "Closed" 1 "Opened";
VAL_ 1041 PASSENGER_REAR_DOOR 0 "Closed" 1 "Opened";
VAL_ 1144 DRIVE_MODE2 3 "Set Sport" 1 "Set Normal" 2 "Set Eco";
VAL_ 1240 DISTANCE_UNIT 1 "Miles" 0 "Kilometers";
